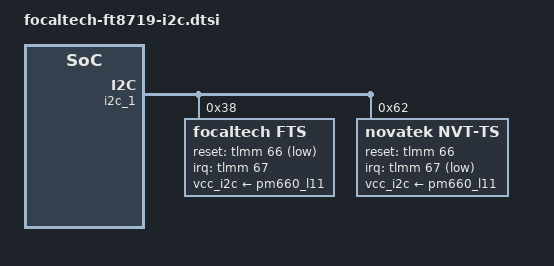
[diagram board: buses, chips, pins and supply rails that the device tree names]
/*
 * This program is free software; you can redistribute it and/or modify
 * it under the terms of the GNU General Public License as published by
 * the Free Software Foundation; either version 2 of the License, or
 * (at your option) any later version.
 *
 * This program is distributed in the hope that it will be useful, but WITHOUT
 * ANY WARRANTY; without even the implied warranty of MERCHANTABILITY or
 * FITNESS FOR A PARTICULAR PURPOSE.  See the GNU General Public License for
 * more details.
 *
 */


&i2c_1{
	status = "ok";
		focaltech@38{
				compatible = "focaltech,fts";
				reg = <0x38>;
				interrupt-parent = <&tlmm>;
				interrupts = <67 0x02>;
				vcc_i2c-supply=<&pm660_l11>;
				focaltech,reset-gpio = <&tlmm 66 0x01>;
				focaltech,irq-gpio = <&tlmm 67 0x02>;
				focaltech,max-touch-number = <10>;
				focaltech,display-coords =  <0 0 1080 2280>;

				pinctrl-names = "pmx_ts_active","pmx_ts_suspend";
				pinctrl-0 = <&ts_active>;
				pinctrl-1 = <&ts_int_suspend &ts_reset_suspend>;

				focaltech,have-key;
				focaltech,key-number = <0>;
				focaltech,keys = <139 102 158>;
				focaltech,key-y-coord = <2500>;
				focaltech,key-x-coords = <200 600 800>;
		};

		/* Novatek device tree node */

	novatek@62 {
		compatible = "novatek,NVT-ts";
		reg = <0x62>;
		status = "ok";

		vcc_i2c-supply=<&pm660_l11>;

		novatek,reset-gpio = <&tlmm 66 0x00>;
		novatek,irq-gpio = <&tlmm 67 0x2001>;

		/* MP */
		novatek,mp-support-dt;

		novatek-mp-criteria-590B@0 {
			#address-cells = <1>;
			#size-cells = <0>;
			compatible = "novatek-mp-criteria-590B";

			/* MP Config */
			IC_X_CFG_SIZE = <18>;
			IC_Y_CFG_SIZE = <36>;
			IC_KEY_CFG_SIZE = <4>;
			X_Channel = <18>;
			Y_Channel = <36>;
			  AIN_X = <0 1 2 3 4 5 6 7 8 9 10 11 12 13 14 15 16 17>;

			  AIN_Y = <0 1 2 3 4 5 6 7 8 9 10 11 12 13 14 15 16 17
							18 19 20 21 22 23 24 25 26 27 28 29 30 31 32 33 34 35>;

			AIN_KEY = <0 1 2 0xFF>;

			/* MP Criteria */
			PS_Config_Lmt_Short_Rawdata_P = <
				14000 14000 14000 14000 14000 14000 14000 14000 14000 14000 14000 14000 14000 14000 14000 14000 14000 14000
				14000 14000 14000 14000 14000 14000 14000 14000 14000 14000 14000 14000 14000 14000 14000 14000 14000 14000
				14000 14000 14000 14000 14000 14000 14000 14000 14000 14000 14000 14000 14000 14000 14000 14000 14000 14000
				14000 14000 14000 14000 14000 14000 14000 14000 14000 14000 14000 14000 14000 14000 14000 14000 14000 14000
				14000 14000 14000 14000 14000 14000 14000 14000 14000 14000 14000 14000 14000 14000 14000 14000 14000 14000
				14000 14000 14000 14000 14000 14000 14000 14000 14000 14000 14000 14000 14000 14000 14000 14000 14000 14000
				14000 14000 14000 14000 14000 14000 14000 14000 14000 14000 14000 14000 14000 14000 14000 14000 14000 14000
				14000 14000 14000 14000 14000 14000 14000 14000 14000 14000 14000 14000 14000 14000 14000 14000 14000 14000
				14000 14000 14000 14000 14000 14000 14000 14000 14000 14000 14000 14000 14000 14000 14000 14000 14000 14000
				14000 14000 14000 14000 14000 14000 14000 14000 14000 14000 14000 14000 14000 14000 14000 14000 14000 14000
				14000 14000 14000 14000 14000 14000 14000 14000 14000 14000 14000 14000 14000 14000 14000 14000 14000 14000
				14000 14000 14000 14000 14000 14000 14000 14000 14000 14000 14000 14000 14000 14000 14000 14000 14000 14000
				14000 14000 14000 14000 14000 14000 14000 14000 14000 14000 14000 14000 14000 14000 14000 14000 14000 14000
				14000 14000 14000 14000 14000 14000 14000 14000 14000 14000 14000 14000 14000 14000 14000 14000 14000 14000
				14000 14000 14000 14000 14000 14000 14000 14000 14000 14000 14000 14000 14000 14000 14000 14000 14000 14000
				14000 14000 14000 14000 14000 14000 14000 14000 14000 14000 14000 14000 14000 14000 14000 14000 14000 14000
				14000 14000 14000 14000 14000 14000 14000 14000 14000 14000 14000 14000 14000 14000 14000 14000 14000 14000
				14000 14000 14000 14000 14000 14000 14000 14000 14000 14000 14000 14000 14000 14000 14000 14000 14000 14000
				14000 14000 14000 14000 14000 14000 14000 14000 14000 14000 14000 14000 14000 14000 14000 14000 14000 14000
				14000 14000 14000 14000 14000 14000 14000 14000 14000 14000 14000 14000 14000 14000 14000 14000 14000 14000
				14000 14000 14000 14000 14000 14000 14000 14000 14000 14000 14000 14000 14000 14000 14000 14000 14000 14000
				14000 14000 14000 14000 14000 14000 14000 14000 14000 14000 14000 14000 14000 14000 14000 14000 14000 14000
				14000 14000 14000 14000 14000 14000 14000 14000 14000 14000 14000 14000 14000 14000 14000 14000 14000 14000
				14000 14000 14000 14000 14000 14000 14000 14000 14000 14000 14000 14000 14000 14000 14000 14000 14000 14000
				14000 14000 14000 14000 14000 14000 14000 14000 14000 14000 14000 14000 14000 14000 14000 14000 14000 14000
				14000 14000 14000 14000 14000 14000 14000 14000 14000 14000 14000 14000 14000 14000 14000 14000 14000 14000
				14000 14000 14000 14000 14000 14000 14000 14000 14000 14000 14000 14000 14000 14000 14000 14000 14000 14000
				14000 14000 14000 14000 14000 14000 14000 14000 14000 14000 14000 14000 14000 14000 14000 14000 14000 14000
				14000 14000 14000 14000 14000 14000 14000 14000 14000 14000 14000 14000 14000 14000 14000 14000 14000 14000
				14000 14000 14000 14000 14000 14000 14000 14000 14000 14000 14000 14000 14000 14000 14000 14000 14000 14000
				14000 14000 14000 14000 14000 14000 14000 14000 14000 14000 14000 14000 14000 14000 14000 14000 14000 14000
				14000 14000 14000 14000 14000 14000 14000 14000 14000 14000 14000 14000 14000 14000 14000 14000 14000 14000
				14000 14000 14000 14000 14000 14000 14000 14000 14000 14000 14000 14000 14000 14000 14000 14000 14000 14000
				14000 14000 14000 14000 14000 14000 14000 14000 14000 14000 14000 14000 14000 14000 14000 14000 14000 14000
				14000 14000 14000 14000 14000 14000 14000 14000 14000 14000 14000 14000 14000 14000 14000 14000 14000 14000
				14000 14000 14000 14000 14000 14000 14000 14000 14000 14000 14000 14000 14000 14000 14000 14000 14000 14000
				20000 20000 20000>;

			PS_Config_Lmt_Short_Rawdata_N = <
				11000 11000 11000 11000 11000 11000 11000 11000 11000 11000 11000 11000 11000 11000 11000 11000 11000 11000
				11000 11000 11000 11000 11000 11000 11000 11000 11000 11000 11000 11000 11000 11000 11000 11000 11000 11000
				11000 11000 11000 11000 11000 11000 11000 11000 11000 11000 11000 11000 11000 11000 11000 11000 11000 11000
				11000 11000 11000 11000 11000 11000 11000 11000 11000 11000 11000 11000 11000 11000 11000 11000 11000 11000
				11000 11000 11000 11000 11000 11000 11000 11000 11000 11000 11000 11000 11000 11000 11000 11000 11000 11000
				11000 11000 11000 11000 11000 11000 11000 11000 11000 11000 11000 11000 11000 11000 11000 11000 11000 11000
				11000 11000 11000 11000 11000 11000 11000 11000 11000 11000 11000 11000 11000 11000 11000 11000 11000 11000
				11000 11000 11000 11000 11000 11000 11000 11000 11000 11000 11000 11000 11000 11000 11000 11000 11000 11000
				11000 11000 11000 11000 11000 11000 11000 11000 11000 11000 11000 11000 11000 11000 11000 11000 11000 11000
				11000 11000 11000 11000 11000 11000 11000 11000 11000 11000 11000 11000 11000 11000 11000 11000 11000 11000
				11000 11000 11000 11000 11000 11000 11000 11000 11000 11000 11000 11000 11000 11000 11000 11000 11000 11000
				11000 11000 11000 11000 11000 11000 11000 11000 11000 11000 11000 11000 11000 11000 11000 11000 11000 11000
				11000 11000 11000 11000 11000 11000 11000 11000 11000 11000 11000 11000 11000 11000 11000 11000 11000 11000
				11000 11000 11000 11000 11000 11000 11000 11000 11000 11000 11000 11000 11000 11000 11000 11000 11000 11000
				11000 11000 11000 11000 11000 11000 11000 11000 11000 11000 11000 11000 11000 11000 11000 11000 11000 11000
				11000 11000 11000 11000 11000 11000 11000 11000 11000 11000 11000 11000 11000 11000 11000 11000 11000 11000
				11000 11000 11000 11000 11000 11000 11000 11000 11000 11000 11000 11000 11000 11000 11000 11000 11000 11000
				11000 11000 11000 11000 11000 11000 11000 11000 11000 11000 11000 11000 11000 11000 11000 11000 11000 11000
				11000 11000 11000 11000 11000 11000 11000 11000 11000 11000 11000 11000 11000 11000 11000 11000 11000 11000
				11000 11000 11000 11000 11000 11000 11000 11000 11000 11000 11000 11000 11000 11000 11000 11000 11000 11000
				11000 11000 11000 11000 11000 11000 11000 11000 11000 11000 11000 11000 11000 11000 11000 11000 11000 11000
				11000 11000 11000 11000 11000 11000 11000 11000 11000 11000 11000 11000 11000 11000 11000 11000 11000 11000
				11000 11000 11000 11000 11000 11000 11000 11000 11000 11000 11000 11000 11000 11000 11000 11000 11000 11000
				11000 11000 11000 11000 11000 11000 11000 11000 11000 11000 11000 11000 11000 11000 11000 11000 11000 11000
				11000 11000 11000 11000 11000 11000 11000 11000 11000 11000 11000 11000 11000 11000 11000 11000 11000 11000
				11000 11000 11000 11000 11000 11000 11000 11000 11000 11000 11000 11000 11000 11000 11000 11000 11000 11000
				11000 11000 11000 11000 11000 11000 11000 11000 11000 11000 11000 11000 11000 11000 11000 11000 11000 11000
				11000 11000 11000 11000 11000 11000 11000 11000 11000 11000 11000 11000 11000 11000 11000 11000 11000 11000
				11000 11000 11000 11000 11000 11000 11000 11000 11000 11000 11000 11000 11000 11000 11000 11000 11000 11000
				11000 11000 11000 11000 11000 11000 11000 11000 11000 11000 11000 11000 11000 11000 11000 11000 11000 11000
				11000 11000 11000 11000 11000 11000 11000 11000 11000 11000 11000 11000 11000 11000 11000 11000 11000 11000
				11000 11000 11000 11000 11000 11000 11000 11000 11000 11000 11000 11000 11000 11000 11000 11000 11000 11000
				11000 11000 11000 11000 11000 11000 11000 11000 11000 11000 11000 11000 11000 11000 11000 11000 11000 11000
				11000 11000 11000 11000 11000 11000 11000 11000 11000 11000 11000 11000 11000 11000 11000 11000 11000 11000
				11000 11000 11000 11000 11000 11000 11000 11000 11000 11000 11000 11000 11000 11000 11000 11000 11000 11000
				11000 11000 11000 11000 11000 11000 11000 11000 11000 11000 11000 11000 11000 11000 11000 11000 11000 11000
				11550 11550 11550>;

			PS_Config_Lmt_Short_Diff_P = <
				6300 6300 6300 6300 6300 6300 6300 6300 6300 6300 6300 6300 6300 6300 6300 6300 6300 6300
				6300 6300 6300 6300 6300 6300 6300 6300 6300 6300 6300 6300 6300 6300 6300 6300 6300 6300
				6300 6300 6300 6300 6300 6300 6300 6300 6300 6300 6300 6300 6300 6300 6300 6300 6300 6300
				6300 6300 6300 6300 6300 6300 6300 6300 6300 6300 6300 6300 6300 6300 6300 6300 6300 6300
				6300 6300 6300 6300 6300 6300 6300 6300 6300 6300 6300 6300 6300 6300 6300 6300 6300 6300
				6300 6300 6300 6300 6300 6300 6300 6300 6300 6300 6300 6300 6300 6300 6300 6300 6300 6300
				6300 6300 6300 6300 6300 6300 6300 6300 6300 6300 6300 6300 6300 6300 6300 6300 6300 6300
				6300 6300 6300 6300 6300 6300 6300 6300 6300 6300 6300 6300 6300 6300 6300 6300 6300 6300
				6300 6300 6300 6300 6300 6300 6300 6300 6300 6300 6300 6300 6300 6300 6300 6300 6300 6300
				6300 6300 6300 6300 6300 6300 6300 6300 6300 6300 6300 6300 6300 6300 6300 6300 6300 6300
				6300 6300 6300 6300 6300 6300 6300 6300 6300 6300 6300 6300 6300 6300 6300 6300 6300 6300
				6300 6300 6300 6300 6300 6300 6300 6300 6300 6300 6300 6300 6300 6300 6300 6300 6300 6300
				6300 6300 6300 6300 6300 6300 6300 6300 6300 6300 6300 6300 6300 6300 6300 6300 6300 6300
				6300 6300 6300 6300 6300 6300 6300 6300 6300 6300 6300 6300 6300 6300 6300 6300 6300 6300
				6300 6300 6300 6300 6300 6300 6300 6300 6300 6300 6300 6300 6300 6300 6300 6300 6300 6300
				6300 6300 6300 6300 6300 6300 6300 6300 6300 6300 6300 6300 6300 6300 6300 6300 6300 6300
				6300 6300 6300 6300 6300 6300 6300 6300 6300 6300 6300 6300 6300 6300 6300 6300 6300 6300
				6300 6300 6300 6300 6300 6300 6300 6300 6300 6300 6300 6300 6300 6300 6300 6300 6300 6300
				6300 6300 6300 6300 6300 6300 6300 6300 6300 6300 6300 6300 6300 6300 6300 6300 6300 6300
				6300 6300 6300 6300 6300 6300 6300 6300 6300 6300 6300 6300 6300 6300 6300 6300 6300 6300
				6300 6300 6300 6300 6300 6300 6300 6300 6300 6300 6300 6300 6300 6300 6300 6300 6300 6300
				6300 6300 6300 6300 6300 6300 6300 6300 6300 6300 6300 6300 6300 6300 6300 6300 6300 6300
				6300 6300 6300 6300 6300 6300 6300 6300 6300 6300 6300 6300 6300 6300 6300 6300 6300 6300
				6300 6300 6300 6300 6300 6300 6300 6300 6300 6300 6300 6300 6300 6300 6300 6300 6300 6300
				6300 6300 6300 6300 6300 6300 6300 6300 6300 6300 6300 6300 6300 6300 6300 6300 6300 6300
				6300 6300 6300 6300 6300 6300 6300 6300 6300 6300 6300 6300 6300 6300 6300 6300 6300 6300
				6300 6300 6300 6300 6300 6300 6300 6300 6300 6300 6300 6300 6300 6300 6300 6300 6300 6300
				6300 6300 6300 6300 6300 6300 6300 6300 6300 6300 6300 6300 6300 6300 6300 6300 6300 6300
				6300 6300 6300 6300 6300 6300 6300 6300 6300 6300 6300 6300 6300 6300 6300 6300 6300 6300
				6300 6300 6300 6300 6300 6300 6300 6300 6300 6300 6300 6300 6300 6300 6300 6300 6300 6300
				6300 6300 6300 6300 6300 6300 6300 6300 6300 6300 6300 6300 6300 6300 6300 6300 6300 6300
				6300 6300 6300 6300 6300 6300 6300 6300 6300 6300 6300 6300 6300 6300 6300 6300 6300 6300
				6300 6300 6300>;

			PS_Config_Lmt_Short_Diff_N = <
				0 0 0 0 0 0 0 0 0 0 0 0 0 0 0 0 0 0
				0 0 0 0 0 0 0 0 0 0 0 0 0 0 0 0 0 0
				0 0 0 0 0 0 0 0 0 0 0 0 0 0 0 0 0 0
				0 0 0 0 0 0 0 0 0 0 0 0 0 0 0 0 0 0
				0 0 0 0 0 0 0 0 0 0 0 0 0 0 0 0 0 0
				0 0 0 0 0 0 0 0 0 0 0 0 0 0 0 0 0 0
				0 0 0 0 0 0 0 0 0 0 0 0 0 0 0 0 0 0
				0 0 0 0 0 0 0 0 0 0 0 0 0 0 0 0 0 0
				0 0 0 0 0 0 0 0 0 0 0 0 0 0 0 0 0 0
				0 0 0 0 0 0 0 0 0 0 0 0 0 0 0 0 0 0
				0 0 0 0 0 0 0 0 0 0 0 0 0 0 0 0 0 0
				0 0 0 0 0 0 0 0 0 0 0 0 0 0 0 0 0 0
				0 0 0 0 0 0 0 0 0 0 0 0 0 0 0 0 0 0
				0 0 0 0 0 0 0 0 0 0 0 0 0 0 0 0 0 0
				0 0 0 0 0 0 0 0 0 0 0 0 0 0 0 0 0 0
				0 0 0 0 0 0 0 0 0 0 0 0 0 0 0 0 0 0
				0 0 0 0 0 0 0 0 0 0 0 0 0 0 0 0 0 0
				0 0 0 0 0 0 0 0 0 0 0 0 0 0 0 0 0 0
				0 0 0 0 0 0 0 0 0 0 0 0 0 0 0 0 0 0
				0 0 0 0 0 0 0 0 0 0 0 0 0 0 0 0 0 0
				0 0 0 0 0 0 0 0 0 0 0 0 0 0 0 0 0 0
				0 0 0 0 0 0 0 0 0 0 0 0 0 0 0 0 0 0
				0 0 0 0 0 0 0 0 0 0 0 0 0 0 0 0 0 0
				0 0 0 0 0 0 0 0 0 0 0 0 0 0 0 0 0 0
				0 0 0 0 0 0 0 0 0 0 0 0 0 0 0 0 0 0
				0 0 0 0 0 0 0 0 0 0 0 0 0 0 0 0 0 0
				0 0 0 0 0 0 0 0 0 0 0 0 0 0 0 0 0 0
				0 0 0 0 0 0 0 0 0 0 0 0 0 0 0 0 0 0
				0 0 0 0 0 0 0 0 0 0 0 0 0 0 0 0 0 0
				0 0 0 0 0 0 0 0 0 0 0 0 0 0 0 0 0 0
				0 0 0 0 0 0 0 0 0 0 0 0 0 0 0 0 0 0
				0 0 0 0 0 0 0 0 0 0 0 0 0 0 0 0 0 0
				0 0 0>;

			PS_Config_Lmt_Short_Base_P = <
				2000 2000 2000 2000 2000 2000 2000 2000 2000 2000 2000 2000 2000 2000 2000 2000 2000 2000
				2000 2000 2000 2000 2000 2000 2000 2000 2000 2000 2000 2000 2000 2000 2000 2000 2000 2000
				2000 2000 2000 2000 2000 2000 2000 2000 2000 2000 2000 2000 2000 2000 2000 2000 2000 2000
				2000 2000 2000 2000 2000 2000 2000 2000 2000 2000 2000 2000 2000 2000 2000 2000 2000 2000
				2000 2000 2000 2000 2000 2000 2000 2000 2000 2000 2000 2000 2000 2000 2000 2000 2000 2000
				2000 2000 2000 2000 2000 2000 2000 2000 2000 2000 2000 2000 2000 2000 2000 2000 2000 2000
				2000 2000 2000 2000 2000 2000 2000 2000 2000 2000 2000 2000 2000 2000 2000 2000 2000 2000
				2000 2000 2000 2000 2000 2000 2000 2000 2000 2000 2000 2000 2000 2000 2000 2000 2000 2000
				2000 2000 2000 2000 2000 2000 2000 2000 2000 2000 2000 2000 2000 2000 2000 2000 2000 2000
				2000 2000 2000 2000 2000 2000 2000 2000 2000 2000 2000 2000 2000 2000 2000 2000 2000 2000
				2000 2000 2000 2000 2000 2000 2000 2000 2000 2000 2000 2000 2000 2000 2000 2000 2000 2000
				2000 2000 2000 2000 2000 2000 2000 2000 2000 2000 2000 2000 2000 2000 2000 2000 2000 2000
				2000 2000 2000 2000 2000 2000 2000 2000 2000 2000 2000 2000 2000 2000 2000 2000 2000 2000
				2000 2000 2000 2000 2000 2000 2000 2000 2000 2000 2000 2000 2000 2000 2000 2000 2000 2000
				2000 2000 2000 2000 2000 2000 2000 2000 2000 2000 2000 2000 2000 2000 2000 2000 2000 2000
				2000 2000 2000 2000 2000 2000 2000 2000 2000 2000 2000 2000 2000 2000 2000 2000 2000 2000
				2000 2000 2000 2000 2000 2000 2000 2000 2000 2000 2000 2000 2000 2000 2000 2000 2000 2000
				2000 2000 2000 2000 2000 2000 2000 2000 2000 2000 2000 2000 2000 2000 2000 2000 2000 2000
				2000 2000 2000 2000 2000 2000 2000 2000 2000 2000 2000 2000 2000 2000 2000 2000 2000 2000
				2000 2000 2000 2000 2000 2000 2000 2000 2000 2000 2000 2000 2000 2000 2000 2000 2000 2000
				2000 2000 2000 2000 2000 2000 2000 2000 2000 2000 2000 2000 2000 2000 2000 2000 2000 2000
				2000 2000 2000 2000 2000 2000 2000 2000 2000 2000 2000 2000 2000 2000 2000 2000 2000 2000
				2000 2000 2000 2000 2000 2000 2000 2000 2000 2000 2000 2000 2000 2000 2000 2000 2000 2000
				2000 2000 2000 2000 2000 2000 2000 2000 2000 2000 2000 2000 2000 2000 2000 2000 2000 2000
				2000 2000 2000 2000 2000 2000 2000 2000 2000 2000 2000 2000 2000 2000 2000 2000 2000 2000
				2000 2000 2000 2000 2000 2000 2000 2000 2000 2000 2000 2000 2000 2000 2000 2000 2000 2000
				2000 2000 2000 2000 2000 2000 2000 2000 2000 2000 2000 2000 2000 2000 2000 2000 2000 2000
				2000 2000 2000 2000 2000 2000 2000 2000 2000 2000 2000 2000 2000 2000 2000 2000 2000 2000
				2000 2000 2000 2000 2000 2000 2000 2000 2000 2000 2000 2000 2000 2000 2000 2000 2000 2000
				2000 2000 2000 2000 2000 2000 2000 2000 2000 2000 2000 2000 2000 2000 2000 2000 2000 2000
				2000 2000 2000 2000 2000 2000 2000 2000 2000 2000 2000 2000 2000 2000 2000 2000 2000 2000
				2000 2000 2000 2000 2000 2000 2000 2000 2000 2000 2000 2000 2000 2000 2000 2000 2000 2000
				2000 2000 2000>;

			PS_Config_Lmt_Short_Base_N = <
				(-2000) (-2000) (-2000) (-2000) (-2000) (-2000) (-2000) (-2000) (-2000) (-2000) (-2000) (-2000) (-2000) (-2000) (-2000) (-2000) (-2000) (-2000)
				(-2000) (-2000) (-2000) (-2000) (-2000) (-2000) (-2000) (-2000) (-2000) (-2000) (-2000) (-2000) (-2000) (-2000) (-2000) (-2000) (-2000) (-2000)
				(-2000) (-2000) (-2000) (-2000) (-2000) (-2000) (-2000) (-2000) (-2000) (-2000) (-2000) (-2000) (-2000) (-2000) (-2000) (-2000) (-2000) (-2000)
				(-2000) (-2000) (-2000) (-2000) (-2000) (-2000) (-2000) (-2000) (-2000) (-2000) (-2000) (-2000) (-2000) (-2000) (-2000) (-2000) (-2000) (-2000)
				(-2000) (-2000) (-2000) (-2000) (-2000) (-2000) (-2000) (-2000) (-2000) (-2000) (-2000) (-2000) (-2000) (-2000) (-2000) (-2000) (-2000) (-2000)
				(-2000) (-2000) (-2000) (-2000) (-2000) (-2000) (-2000) (-2000) (-2000) (-2000) (-2000) (-2000) (-2000) (-2000) (-2000) (-2000) (-2000) (-2000)
				(-2000) (-2000) (-2000) (-2000) (-2000) (-2000) (-2000) (-2000) (-2000) (-2000) (-2000) (-2000) (-2000) (-2000) (-2000) (-2000) (-2000) (-2000)
				(-2000) (-2000) (-2000) (-2000) (-2000) (-2000) (-2000) (-2000) (-2000) (-2000) (-2000) (-2000) (-2000) (-2000) (-2000) (-2000) (-2000) (-2000)
				(-2000) (-2000) (-2000) (-2000) (-2000) (-2000) (-2000) (-2000) (-2000) (-2000) (-2000) (-2000) (-2000) (-2000) (-2000) (-2000) (-2000) (-2000)
				(-2000) (-2000) (-2000) (-2000) (-2000) (-2000) (-2000) (-2000) (-2000) (-2000) (-2000) (-2000) (-2000) (-2000) (-2000) (-2000) (-2000) (-2000)
				(-2000) (-2000) (-2000) (-2000) (-2000) (-2000) (-2000) (-2000) (-2000) (-2000) (-2000) (-2000) (-2000) (-2000) (-2000) (-2000) (-2000) (-2000)
				(-2000) (-2000) (-2000) (-2000) (-2000) (-2000) (-2000) (-2000) (-2000) (-2000) (-2000) (-2000) (-2000) (-2000) (-2000) (-2000) (-2000) (-2000)
				(-2000) (-2000) (-2000) (-2000) (-2000) (-2000) (-2000) (-2000) (-2000) (-2000) (-2000) (-2000) (-2000) (-2000) (-2000) (-2000) (-2000) (-2000)
				(-2000) (-2000) (-2000) (-2000) (-2000) (-2000) (-2000) (-2000) (-2000) (-2000) (-2000) (-2000) (-2000) (-2000) (-2000) (-2000) (-2000) (-2000)
				(-2000) (-2000) (-2000) (-2000) (-2000) (-2000) (-2000) (-2000) (-2000) (-2000) (-2000) (-2000) (-2000) (-2000) (-2000) (-2000) (-2000) (-2000)
				(-2000) (-2000) (-2000) (-2000) (-2000) (-2000) (-2000) (-2000) (-2000) (-2000) (-2000) (-2000) (-2000) (-2000) (-2000) (-2000) (-2000) (-2000)
				(-2000) (-2000) (-2000) (-2000) (-2000) (-2000) (-2000) (-2000) (-2000) (-2000) (-2000) (-2000) (-2000) (-2000) (-2000) (-2000) (-2000) (-2000)
				(-2000) (-2000) (-2000) (-2000) (-2000) (-2000) (-2000) (-2000) (-2000) (-2000) (-2000) (-2000) (-2000) (-2000) (-2000) (-2000) (-2000) (-2000)
				(-2000) (-2000) (-2000) (-2000) (-2000) (-2000) (-2000) (-2000) (-2000) (-2000) (-2000) (-2000) (-2000) (-2000) (-2000) (-2000) (-2000) (-2000)
				(-2000) (-2000) (-2000) (-2000) (-2000) (-2000) (-2000) (-2000) (-2000) (-2000) (-2000) (-2000) (-2000) (-2000) (-2000) (-2000) (-2000) (-2000)
				(-2000) (-2000) (-2000) (-2000) (-2000) (-2000) (-2000) (-2000) (-2000) (-2000) (-2000) (-2000) (-2000) (-2000) (-2000) (-2000) (-2000) (-2000)
				(-2000) (-2000) (-2000) (-2000) (-2000) (-2000) (-2000) (-2000) (-2000) (-2000) (-2000) (-2000) (-2000) (-2000) (-2000) (-2000) (-2000) (-2000)
				(-2000) (-2000) (-2000) (-2000) (-2000) (-2000) (-2000) (-2000) (-2000) (-2000) (-2000) (-2000) (-2000) (-2000) (-2000) (-2000) (-2000) (-2000)
				(-2000) (-2000) (-2000) (-2000) (-2000) (-2000) (-2000) (-2000) (-2000) (-2000) (-2000) (-2000) (-2000) (-2000) (-2000) (-2000) (-2000) (-2000)
				(-2000) (-2000) (-2000) (-2000) (-2000) (-2000) (-2000) (-2000) (-2000) (-2000) (-2000) (-2000) (-2000) (-2000) (-2000) (-2000) (-2000) (-2000)
				(-2000) (-2000) (-2000) (-2000) (-2000) (-2000) (-2000) (-2000) (-2000) (-2000) (-2000) (-2000) (-2000) (-2000) (-2000) (-2000) (-2000) (-2000)
				(-2000) (-2000) (-2000) (-2000) (-2000) (-2000) (-2000) (-2000) (-2000) (-2000) (-2000) (-2000) (-2000) (-2000) (-2000) (-2000) (-2000) (-2000)
				(-2000) (-2000) (-2000) (-2000) (-2000) (-2000) (-2000) (-2000) (-2000) (-2000) (-2000) (-2000) (-2000) (-2000) (-2000) (-2000) (-2000) (-2000)
				(-2000) (-2000) (-2000) (-2000) (-2000) (-2000) (-2000) (-2000) (-2000) (-2000) (-2000) (-2000) (-2000) (-2000) (-2000) (-2000) (-2000) (-2000)
				(-2000) (-2000) (-2000) (-2000) (-2000) (-2000) (-2000) (-2000) (-2000) (-2000) (-2000) (-2000) (-2000) (-2000) (-2000) (-2000) (-2000) (-2000)
				(-2000) (-2000) (-2000) (-2000) (-2000) (-2000) (-2000) (-2000) (-2000) (-2000) (-2000) (-2000) (-2000) (-2000) (-2000) (-2000) (-2000) (-2000)
				(-2000) (-2000) (-2000) (-2000) (-2000) (-2000) (-2000) (-2000) (-2000) (-2000) (-2000) (-2000) (-2000) (-2000) (-2000) (-2000) (-2000) (-2000)
				(-2000) (-2000) (-2000)>;

			PS_Config_Lmt_Open_Rawdata_P = <
				2125 3088 3111 3114 2187 5120 5120 5120 5120 5120 5120 5120 5120 2144 3136 3151 3116 2144
				2868 2880 2868 2868 2258 2293 2274 2269 2261 2269 2275 2285 2295 2257 2876 2886 2892 2896
				2934 2919 2909 2910 2901 2887 2885 2870 2857 2873 2880 2894 2888 2891 2916 2926 2930 2945
				2924 2919 2918 2919 2910 2894 2891 2874 2865 2876 2882 2903 2898 2903 2927 2936 2942 2951
				2934 2912 2906 2906 2895 2879 2877 2859 2850 2890 2894 2905 2903 2908 2931 2940 2946 2956
				2939 2925 2920 2919 2908 2891 2889 2871 2863 2898 2903 2912 2911 2917 2941 2947 2954 2961
				2924 2925 2918 2916 2906 2889 2886 2867 2864 2888 2892 2900 2902 2908 2930 2937 2943 2948
				2935 2938 2925 2922 2919 2903 2899 2880 2879 2903 2906 2901 2896 2918 2939 2943 2951 2954
				2933 2932 2927 2922 2912 2896 2893 2872 2872 2894 2897 2902 2896 2910 2933 2936 2942 2943
				2944 2926 2922 2916 2907 2890 2886 2868 2867 2898 2898 2903 2899 2912 2934 2937 2943 2943
				2936 2938 2935 2928 2909 2895 2898 2883 2881 2904 2899 2905 2904 2910 2930 2941 2946 2944
				2928 2932 2932 2924 2911 2896 2893 2878 2878 2919 2913 2919 2918 2932 2949 2952 2957 2955
				2939 2930 2929 2921 2908 2894 2891 2876 2875 2907 2902 2908 2907 2919 2937 2941 2943 2940
				2932 2926 2924 2916 2902 2890 2886 2876 2873 2904 2899 2904 2903 2917 2933 2937 2936 2934
				2928 2922 2926 2916 2902 2890 2881 2875 2875 2907 2901 2910 2907 2920 2936 2934 2931 2934
				2923 2926 2929 2920 2906 2892 2895 2885 2880 2897 2893 2900 2899 2914 2927 2931 2928 2925
				2922 2915 2918 2908 2894 2880 2882 2883 2867 2890 2884 2891 2892 2905 2918 2922 2918 2917
				2923 2911 2916 2907 2890 2878 2880 2876 2866 2903 2900 2904 2904 2918 2928 2933 2928 2931
				2910 2904 2906 2896 2883 2869 2872 2868 2855 2882 2876 2884 2884 2900 2910 2914 2908 2906
				2904 2902 2903 2894 2879 2867 2871 2867 2861 2880 2874 2885 2884 2900 2908 2913 2905 2910
				2895 2889 2890 2881 2866 2854 2858 2854 2854 2880 2873 2884 2883 2899 2906 2910 2907 2909
				2889 2891 2897 2888 2871 2860 2866 2860 2859 2876 2867 2883 2881 2898 2903 2908 2905 2908
				2880 2880 2881 2871 2855 2845 2851 2847 2844 2866 2857 2871 2869 2886 2891 2893 2889 2890
				2645 2631 2635 2627 2617 2606 2609 2605 2601 2623 2620 2633 2637 2647 2651 2651 2645 2651
				2636 2618 2623 2617 2608 2596 2601 2596 2592 2615 2612 2629 2629 2640 2645 2644 2640 2646
				2631 2630 2631 2624 2618 2607 2614 2607 2603 2617 2616 2629 2627 2641 2646 2646 2642 2650
				2616 2617 2619 2612 2605 2593 2599 2595 2590 2605 2603 2619 2618 2628 2633 2633 2630 2638
				2626 2618 2621 2613 2605 2598 2602 2597 2592 2601 2599 2613 2613 2623 2628 2627 2626 2634
				2611 2609 2611 2603 2593 2585 2595 2587 2582 2585 2584 2597 2596 2604 2608 2611 2611 2621
				2613 2598 2600 2592 2584 2576 2583 2576 2571 2589 2588 2600 2599 2610 2613 2614 2614 2625
				2603 2580 2580 2573 2565 2558 2565 2558 2554 2575 2577 2586 2586 2596 2600 2602 2602 2612
				2592 2581 2581 2574 2565 2559 2567 2559 2555 2571 2571 2581 2581 2592 2594 2596 2599 2608
				2571 2567 2567 2560 2553 2545 2553 2543 2540 2549 2551 2560 2561 2572 2574 2574 2576 2589
				2571 2552 2553 2546 2540 2531 2542 2532 2527 2754 2757 2764 2765 2784 2785 2786 2787 2801
				2518 2503 2502 2497 2490 2480 2494 2480 2475 2497 2502 2519 2506 2514 2519 2524 2526 2542
				2196 2972 2984 2983 2970 2958 2972 2956 2950 2760 2766 2784 2775 2786 2787 2787 2779 2002
				13000 13000 13000>;

			PS_Config_Lmt_Open_Rawdata_N = <
				1221 1775 1788 1790 1257   50   50   50   50   50   50   50   50 1232 1802 1811 1791 1233
				1649 1655 1649 1649 1298 1318 1307 1304 1300 1304 1308 1313 1319 1298 1653 1659 1663 1665
				1687 1678 1672 1672 1668 1659 1659 1649 1642 1651 1655 1663 1660 1662 1676 1682 1684 1693
				1681 1678 1678 1678 1673 1664 1662 1652 1647 1653 1657 1669 1666 1668 1682 1688 1691 1696
				1686 1674 1670 1670 1664 1655 1654 1643 1638 1661 1664 1670 1669 1672 1685 1690 1693 1699
				1689 1681 1679 1678 1671 1662 1661 1650 1646 1666 1668 1674 1673 1677 1690 1694 1698 1702
				1681 1681 1677 1676 1671 1661 1659 1648 1646 1660 1663 1667 1668 1672 1684 1688 1692 1694
				1687 1689 1681 1679 1678 1669 1666 1655 1655 1669 1670 1667 1665 1677 1690 1692 1696 1698
				1686 1685 1682 1680 1674 1665 1663 1651 1651 1664 1665 1668 1665 1673 1686 1688 1691 1691
				1692 1682 1679 1676 1671 1661 1659 1649 1648 1666 1666 1669 1666 1674 1686 1688 1691 1691
				1688 1688 1687 1683 1672 1664 1666 1657 1656 1669 1666 1670 1669 1673 1684 1691 1693 1692
				1683 1685 1685 1681 1673 1665 1663 1655 1654 1678 1674 1678 1677 1685 1695 1697 1700 1699
				1689 1684 1683 1679 1672 1664 1662 1653 1653 1671 1668 1672 1671 1678 1688 1691 1692 1690
				1686 1682 1681 1676 1668 1661 1659 1653 1651 1669 1666 1669 1669 1677 1686 1688 1688 1687
				1683 1680 1682 1676 1668 1661 1656 1652 1652 1671 1667 1673 1671 1679 1687 1686 1685 1687
				1680 1682 1684 1679 1670 1662 1664 1658 1656 1665 1663 1667 1666 1675 1682 1685 1683 1681
				1679 1675 1677 1672 1663 1656 1657 1657 1648 1661 1658 1662 1662 1670 1677 1680 1677 1677
				1680 1674 1676 1671 1661 1654 1656 1653 1647 1668 1667 1669 1669 1677 1683 1686 1683 1685
				1673 1669 1670 1665 1657 1649 1651 1649 1641 1656 1653 1658 1658 1667 1673 1675 1671 1670
				1669 1668 1669 1664 1655 1648 1650 1648 1644 1656 1652 1658 1658 1667 1671 1674 1670 1673
				1664 1661 1661 1656 1647 1640 1643 1640 1640 1656 1652 1658 1657 1667 1670 1673 1671 1672
				1660 1662 1665 1660 1650 1644 1648 1644 1643 1653 1648 1657 1656 1666 1669 1672 1670 1671
				1656 1656 1656 1650 1641 1635 1639 1636 1635 1647 1642 1650 1649 1659 1662 1663 1661 1661
				1520 1512 1515 1510 1504 1498 1499 1497 1495 1508 1506 1514 1516 1521 1524 1524 1520 1524
				1515 1505 1508 1504 1499 1492 1495 1492 1490 1503 1501 1511 1511 1518 1520 1520 1517 1521
				1512 1511 1512 1508 1505 1499 1502 1499 1496 1505 1504 1511 1510 1518 1521 1521 1518 1523
				1503 1504 1505 1501 1497 1491 1494 1492 1489 1497 1496 1505 1505 1510 1513 1513 1512 1516
				1509 1505 1506 1502 1497 1493 1496 1493 1490 1495 1494 1502 1502 1508 1510 1510 1510 1514
				1501 1500 1501 1496 1490 1486 1491 1487 1484 1486 1485 1493 1492 1497 1499 1501 1501 1506
				1502 1494 1495 1490 1485 1481 1485 1481 1478 1488 1488 1494 1494 1500 1502 1503 1503 1509
				1496 1483 1483 1479 1475 1470 1474 1470 1468 1480 1481 1487 1487 1492 1494 1495 1496 1501
				1490 1484 1483 1479 1475 1471 1476 1471 1468 1478 1478 1483 1483 1490 1491 1492 1494 1499
				1478 1476 1475 1471 1467 1463 1467 1462 1460 1465 1466 1471 1472 1478 1479 1479 1481 1488
				1478 1467 1467 1464 1460 1455 1461 1455 1452 1583 1585 1589 1590 1600 1601 1602 1602 1610
				1448 1439 1438 1435 1431 1426 1434 1425 1423 1435 1438 1448 1441 1445 1448 1451 1452 1461
				1262 1708 1715 1714 1707 1700 1708 1699 1696 1586 1590 1600 1595 1601 1602 1602 1597 1151
				6500 6500 6500>;

			PS_Config_Lmt_FW_Rawdata_P = <
				1750 1750 1750 1750 1750 1750 1750 1750 1750 1750 1750 1750 1750 1750 1750 1750 1750 1750
				1750 1750 1750 1750 1750 1750 1750 1750 1750 1750 1750 1750 1750 1750 1750 1750 1750 1750
				1750 1750 1750 1750 1750 1750 1750 1750 1750 1750 1750 1750 1750 1750 1750 1750 1750 1750
				1750 1750 1750 1750 1750 1750 1750 1750 1750 1750 1750 1750 1750 1750 1750 1750 1750 1750
				1750 1750 1750 1750 1750 1750 1750 1750 1750 1750 1750 1750 1750 1750 1750 1750 1750 1750
				1750 1750 1750 1750 1750 1750 1750 1750 1750 1750 1750 1750 1750 1750 1750 1750 1750 1750
				1750 1750 1750 1750 1750 1750 1750 1750 1750 1750 1750 1750 1750 1750 1750 1750 1750 1750
				1750 1750 1750 1750 1750 1750 1750 1750 1750 1750 1750 1750 1750 1750 1750 1750 1750 1750
				1750 1750 1750 1750 1750 1750 1750 1750 1750 1750 1750 1750 1750 1750 1750 1750 1750 1750
				1750 1750 1750 1750 1750 1750 1750 1750 1750 1750 1750 1750 1750 1750 1750 1750 1750 1750
				1750 1750 1750 1750 1750 1750 1750 1750 1750 1750 1750 1750 1750 1750 1750 1750 1750 1750
				1750 1750 1750 1750 1750 1750 1750 1750 1750 1750 1750 1750 1750 1750 1750 1750 1750 1750
				1750 1750 1750 1750 1750 1750 1750 1750 1750 1750 1750 1750 1750 1750 1750 1750 1750 1750
				1750 1750 1750 1750 1750 1750 1750 1750 1750 1750 1750 1750 1750 1750 1750 1750 1750 1750
				1750 1750 1750 1750 1750 1750 1750 1750 1750 1750 1750 1750 1750 1750 1750 1750 1750 1750
				1750 1750 1750 1750 1750 1750 1750 1750 1750 1750 1750 1750 1750 1750 1750 1750 1750 1750
				1750 1750 1750 1750 1750 1750 1750 1750 1750 1750 1750 1750 1750 1750 1750 1750 1750 1750
				1750 1750 1750 1750 1750 1750 1750 1750 1750 1750 1750 1750 1750 1750 1750 1750 1750 1750
				1750 1750 1750 1750 1750 1750 1750 1750 1750 1750 1750 1750 1750 1750 1750 1750 1750 1750
				1750 1750 1750 1750 1750 1750 1750 1750 1750 1750 1750 1750 1750 1750 1750 1750 1750 1750
				1750 1750 1750 1750 1750 1750 1750 1750 1750 1750 1750 1750 1750 1750 1750 1750 1750 1750
				1750 1750 1750 1750 1750 1750 1750 1750 1750 1750 1750 1750 1750 1750 1750 1750 1750 1750
				1750 1750 1750 1750 1750 1750 1750 1750 1750 1750 1750 1750 1750 1750 1750 1750 1750 1750
				1750 1750 1750 1750 1750 1750 1750 1750 1750 1750 1750 1750 1750 1750 1750 1750 1750 1750
				1750 1750 1750 1750 1750 1750 1750 1750 1750 1750 1750 1750 1750 1750 1750 1750 1750 1750
				1750 1750 1750 1750 1750 1750 1750 1750 1750 1750 1750 1750 1750 1750 1750 1750 1750 1750
				1750 1750 1750 1750 1750 1750 1750 1750 1750 1750 1750 1750 1750 1750 1750 1750 1750 1750
				1750 1750 1750 1750 1750 1750 1750 1750 1750 1750 1750 1750 1750 1750 1750 1750 1750 1750
				1750 1750 1750 1750 1750 1750 1750 1750 1750 1750 1750 1750 1750 1750 1750 1750 1750 1750
				1750 1750 1750 1750 1750 1750 1750 1750 1750 1750 1750 1750 1750 1750 1750 1750 1750 1750
				1750 1750 1750 1750 1750 1750 1750 1750 1750 1750 1750 1750 1750 1750 1750 1750 1750 1750
				1750 1750 1750 1750 1750 1750 1750 1750 1750 1750 1750 1750 1750 1750 1750 1750 1750 1750
				1750 1750 1750 1750 1750 1750 1750 1750 1750 1750 1750 1750 1750 1750 1750 1750 1750 1750
				1750 1750 1750 1750 1750 1750 1750 1750 1750 1750 1750 1750 1750 1750 1750 1750 1750 1750
				1750 1750 1750 1750 1750 1750 1750 1750 1750 1750 1750 1750 1750 1750 1750 1750 1750 1750
				1750 1750 1750 1750 1750 1750 1750 1750 1750 1750 1750 1750 1750 1750 1750 1750 1750 1750
				2000 2000 2000>;

			PS_Config_Lmt_FW_Rawdata_N = <
				650 650 650 650 650 650 650 650 650 650 650 650 650 650 650 650 650 650
				650 650 650 650 650 650 650 650 650 650 650 650 650 650 650 650 650 650
				650 650 650 650 650 650 650 650 650 650 650 650 650 650 650 650 650 650
				650 650 650 650 650 650 650 650 650 650 650 650 650 650 650 650 650 650
				650 650 650 650 650 650 650 650 650 650 650 650 650 650 650 650 650 650
				650 650 650 650 650 650 650 650 650 650 650 650 650 650 650 650 650 650
				650 650 650 650 650 650 650 650 650 650 650 650 650 650 650 650 650 650
				650 650 650 650 650 650 650 650 650 650 650 650 650 650 650 650 650 650
				650 650 650 650 650 650 650 650 650 650 650 650 650 650 650 650 650 650
				650 650 650 650 650 650 650 650 650 650 650 650 650 650 650 650 650 650
				650 650 650 650 650 650 650 650 650 650 650 650 650 650 650 650 650 650
				650 650 650 650 650 650 650 650 650 650 650 650 650 650 650 650 650 650
				650 650 650 650 650 650 650 650 650 650 650 650 650 650 650 650 650 650
				650 650 650 650 650 650 650 650 650 650 650 650 650 650 650 650 650 650
				650 650 650 650 650 650 650 650 650 650 650 650 650 650 650 650 650 650
				650 650 650 650 650 650 650 650 650 650 650 650 650 650 650 650 650 650
				650 650 650 650 650 650 650 650 650 650 650 650 650 650 650 650 650 650
				650 650 650 650 650 650 650 650 650 650 650 650 650 650 650 650 650 650
				650 650 650 650 650 650 650 650 650 650 650 650 650 650 650 650 650 650
				650 650 650 650 650 650 650 650 650 650 650 650 650 650 650 650 650 650
				650 650 650 650 650 650 650 650 650 650 650 650 650 650 650 650 650 650
				650 650 650 650 650 650 650 650 650 650 650 650 650 650 650 650 650 650
				650 650 650 650 650 650 650 650 650 650 650 650 650 650 650 650 650 650
				650 650 650 650 650 650 650 650 650 650 650 650 650 650 650 650 650 650
				650 650 650 650 650 650 650 650 650 650 650 650 650 650 650 650 650 650
				650 650 650 650 650 650 650 650 650 650 650 650 650 650 650 650 650 650
				650 650 650 650 650 650 650 650 650 650 650 650 650 650 650 650 650 650
				650 650 650 650 650 650 650 650 650 650 650 650 650 650 650 650 650 650
				650 650 650 650 650 650 650 650 650 650 650 650 650 650 650 650 650 650
				650 650 650 650 650 650 650 650 650 650 650 650 650 650 650 650 650 650
				650 650 650 650 650 650 650 650 650 650 650 650 650 650 650 650 650 650
				650 650 650 650 650 650 650 650 650 650 650 650 650 650 650 650 650 650
				650 650 650 650 650 650 650 650 650 650 650 650 650 650 650 650 650 650
				650 650 650 650 650 650 650 650 650 650 650 650 650 650 650 650 650 650
				650 650 650 650 650 650 650 650 650 650 650 650 650 650 650 650 650 650
				650 650 650 650 650 650 650 650 650 650 650 650 650 650 650 650 650 650
				400 400 400>;

			PS_Config_Lmt_FW_CC_P = <
				118 116 114 113 111 512 512 512 512 512 512 512 512 112 115 116 116 114
				118 116 114 113 111 112 111 111 111 111 115 114 112 111 113 113 114 118
				122 115 113 112 111 110 110 110 109 111 114 114 112 112 113 114 114 118
				124 116 114 113 113 112 111 111 111 112 115 115 114 113 114 115 116 120
				122 115 113 112 111 111 110 110 109 110 113 113 111 111 112 112 113 117
				123 116 115 114 114 113 112 112 111 112 115 114 113 113 114 114 115 119
				121 114 112 112 111 110 110 109 109 112 115 114 113 113 113 114 115 118
				123 116 114 114 113 112 112 111 111 116 117 115 115 114 115 115 116 120
				120 115 113 113 112 111 112 111 110 116 114 113 112 112 112 113 113 118
				122 116 115 115 114 113 113 113 112 118 113 113 112 112 113 113 114 118
				121 114 113 113 112 111 111 111 110 118 113 113 113 112 113 114 114 118
				123 114 113 113 112 111 111 111 111 121 114 114 114 114 114 115 115 120
				120 114 113 113 113 112 112 112 111 119 113 113 113 113 113 114 114 119
				120 116 115 115 114 114 114 115 113 120 114 114 113 113 114 114 115 120
				120 113 112 112 112 111 111 113 110 120 114 114 113 114 115 115 115 120
				122 114 114 113 113 112 113 114 112 120 115 115 114 115 115 115 116 121
				119 114 114 113 113 112 113 114 111 118 113 112 112 112 113 113 114 118
				120 116 115 115 114 114 114 115 113 120 115 114 114 114 114 115 115 121
				120 114 113 112 112 111 112 112 110 119 115 113 113 113 114 114 115 120
				121 115 114 114 113 113 113 113 113 120 115 114 114 114 115 115 116 122
				118 114 114 113 113 112 113 112 112 117 114 112 112 112 113 113 114 120
				120 115 115 115 114 114 115 114 113 118 114 113 112 113 114 114 115 121
				119 113 112 112 111 112 112 112 110 117 113 113 112 113 114 114 115 121
				120 114 113 113 112 112 113 113 111 117 114 115 114 115 115 116 117 123
				117 114 113 113 112 112 113 113 111 114 112 113 112 113 114 114 115 122
				119 116 116 115 115 115 116 117 114 114 113 114 113 114 115 115 116 123
				118 114 113 113 112 113 114 115 112 114 113 113 114 114 115 115 116 123
				121 115 115 114 113 114 115 116 113 115 114 114 115 115 116 117 118 125
				118 115 115 114 114 114 115 116 112 113 112 112 113 113 114 115 116 123
				120 117 116 116 115 116 116 117 114 114 113 113 114 115 116 116 118 125
				119 115 114 113 113 113 113 114 112 113 113 113 114 114 115 116 117 124
				121 116 115 115 114 114 116 116 113 115 115 115 115 116 117 118 120 127
				118 116 115 115 114 114 116 116 113 112 112 112 113 114 114 115 117 124
				120 117 116 116 115 115 118 117 114 112 113 112 113 114 115 116 118 128
				120 114 114 113 113 112 116 115 111 111 115 116 113 113 114 114 115 118
				114 115 113 114 113 113 117 116 113 111 116 117 113 112 113 113 114 113
				119 120 120>;

			PS_Config_Lmt_FW_CC_N = <
				72 71 70 70 68 10 10 10 10 10 10 10 10 68 71 71 71 70
				73 71 70 69 68 68 68 68 68 68 70 70 69 68 69 70 70 73
				75 70 69 69 68 68 67 67 67 68 70 70 69 69 69 70 70 72
				76 71 70 69 69 69 68 68 68 69 71 70 70 70 70 70 71 73
				75 70 69 69 68 68 67 67 67 67 69 69 68 68 69 69 69 72
				75 71 70 70 70 69 69 69 68 69 70 70 69 69 70 70 70 73
				74 70 69 69 68 67 67 67 67 69 70 70 69 69 69 70 70 72
				76 71 70 70 69 69 69 68 68 71 72 71 70 70 70 71 71 74
				74 70 70 69 69 68 68 68 68 71 70 69 69 69 69 69 70 72
				75 71 70 70 70 69 70 69 69 72 69 69 69 69 69 69 70 72
				74 70 69 69 69 68 68 68 68 73 69 69 69 69 69 70 70 72
				75 70 69 69 69 68 68 68 68 74 70 70 70 70 70 70 71 73
				74 70 69 69 69 68 69 69 68 73 69 69 69 69 69 70 70 73
				74 71 71 71 70 70 70 70 69 74 70 70 70 70 70 70 70 73
				74 69 69 69 68 68 68 69 68 74 70 70 69 70 70 70 71 74
				75 70 70 70 69 69 69 70 68 74 71 70 70 70 70 71 71 74
				73 70 70 69 69 69 69 70 68 72 69 69 68 69 69 69 70 73
				74 71 71 70 70 70 70 70 69 73 71 70 70 70 70 70 71 74
				74 70 69 69 69 68 68 69 68 73 70 69 69 69 70 70 70 74
				74 70 70 70 69 69 69 70 69 73 70 70 70 70 70 71 71 75
				73 70 70 70 69 69 69 69 69 72 70 69 68 69 69 69 70 73
				73 71 71 70 70 70 70 70 69 72 70 69 69 69 70 70 70 74
				73 69 69 69 68 68 69 69 68 71 69 69 69 69 70 70 70 74
				73 70 70 69 69 69 69 69 68 72 70 70 70 71 71 71 72 76
				72 70 69 69 69 69 69 70 68 70 69 69 69 69 70 70 71 75
				73 71 71 71 70 70 71 72 70 70 69 70 70 70 70 70 71 75
				72 70 70 69 69 69 70 70 68 70 69 70 70 70 70 71 71 75
				74 71 70 70 70 70 70 71 69 70 70 70 70 71 71 72 72 77
				73 71 70 70 70 70 70 71 69 69 69 69 69 70 70 70 71 75
				73 71 71 71 71 71 71 72 70 70 69 69 70 70 71 71 72 76
				73 70 70 70 69 69 69 70 68 70 69 69 70 70 70 71 72 76
				74 71 71 70 70 70 71 71 69 71 70 70 70 71 72 72 73 78
				73 71 71 70 70 70 71 71 69 69 69 69 69 70 70 71 72 76
				74 71 71 71 70 70 72 72 70 69 69 68 69 70 70 71 73 78
				73 70 70 70 69 69 71 70 68 68 71 71 69 69 70 70 70 73
				70 70 70 70 69 70 72 71 69 68 71 71 69 69 69 69 70 69
				53 54 54>;

			PS_Config_Lmt_FW_CC_I_P = <
				25 25 25 25 25 25 25 25 25 25 25 25 25 25 25 25 25 25
				25 25 25 25 25 25 25 25 25 25 25 25 25 25 25 25 25 25
				25 25 25 25 25 25 25 25 25 25 25 25 25 25 25 25 25 25
				25 25 25 25 25 25 25 25 25 25 25 25 25 25 25 25 25 25
				25 25 25 25 25 25 25 25 25 25 25 25 25 25 25 25 25 25
				25 25 25 25 25 25 25 25 25 25 25 25 25 25 25 25 25 25
				25 25 25 25 25 25 25 25 25 25 25 25 25 25 25 25 25 25
				25 25 25 25 25 25 25 25 25 25 25 25 25 25 25 25 25 25
				25 25 25 25 25 25 25 25 25 25 25 25 25 25 25 25 25 25
				25 25 25 25 25 25 25 25 25 25 25 25 25 25 25 25 25 25
				25 25 25 25 25 25 25 25 25 25 25 25 25 25 25 25 25 25
				25 25 25 25 25 25 25 25 25 25 25 25 25 25 25 25 25 25
				25 25 25 25 25 25 25 25 25 25 25 25 25 25 25 25 25 25
				25 25 25 25 25 25 25 25 25 25 25 25 25 25 25 25 25 25
				25 25 25 25 25 25 25 25 25 25 25 25 25 25 25 25 25 25
				25 25 25 25 25 25 25 25 25 25 25 25 25 25 25 25 25 25
				25 25 25 25 25 25 25 25 25 25 25 25 25 25 25 25 25 25
				25 25 25 25 25 25 25 25 25 25 25 25 25 25 25 25 25 25
				25 25 25 25 25 25 25 25 25 25 25 25 25 25 25 25 25 25
				25 25 25 25 25 25 25 25 25 25 25 25 25 25 25 25 25 25
				25 25 25 25 25 25 25 25 25 25 25 25 25 25 25 25 25 25
				25 25 25 25 25 25 25 25 25 25 25 25 25 25 25 25 25 25
				25 25 25 25 25 25 25 25 25 25 25 25 25 25 25 25 25 25
				25 25 25 25 25 25 25 25 25 25 25 25 25 25 25 25 25 25
				25 25 25 25 25 25 25 25 25 25 25 25 25 25 25 25 25 25
				25 25 25 25 25 25 25 25 25 25 25 25 25 25 25 25 25 25
				25 25 25 25 25 25 25 25 25 25 25 25 25 25 25 25 25 25
				25 25 25 25 25 25 25 25 25 25 25 25 25 25 25 25 25 25
				25 25 25 25 25 25 25 25 25 25 25 25 25 25 25 25 25 25
				25 25 25 25 25 25 25 25 25 25 25 25 25 25 25 25 25 25
				25 25 25 25 25 25 25 25 25 25 25 25 25 25 25 25 25 25
				25 25 25 25 25 25 25 25 25 25 25 25 25 25 25 25 25 25
				25 25 25 25 25 25 25 25 25 25 25 25 25 25 25 25 25 25
				25 25 25 25 25 25 25 25 25 25 25 25 25 25 25 25 25 25
				25 25 25 25 25 25 25 25 25 25 25 25 25 25 25 25 25 25
				25 25 25 25 25 25 25 25 25 25 25 25 25 25 25 25 25 25
				25 25 25>;

			PS_Config_Lmt_FW_CC_I_N = <
				0 0 0 0 0 0 0 0 0 0 0 0 0 0 0 0 0 0
				0 0 0 0 0 0 0 0 0 0 0 0 0 0 0 0 0 0
				0 0 0 0 0 0 0 0 0 0 0 0 0 0 0 0 0 0
				0 0 0 0 0 0 0 0 0 0 0 0 0 0 0 0 0 0
				0 0 0 0 0 0 0 0 0 0 0 0 0 0 0 0 0 0
				0 0 0 0 0 0 0 0 0 0 0 0 0 0 0 0 0 0
				0 0 0 0 0 0 0 0 0 0 0 0 0 0 0 0 0 0
				0 0 0 0 0 0 0 0 0 0 0 0 0 0 0 0 0 0
				0 0 0 0 0 0 0 0 0 0 0 0 0 0 0 0 0 0
				0 0 0 0 0 0 0 0 0 0 0 0 0 0 0 0 0 0
				0 0 0 0 0 0 0 0 0 0 0 0 0 0 0 0 0 0
				0 0 0 0 0 0 0 0 0 0 0 0 0 0 0 0 0 0
				0 0 0 0 0 0 0 0 0 0 0 0 0 0 0 0 0 0
				0 0 0 0 0 0 0 0 0 0 0 0 0 0 0 0 0 0
				0 0 0 0 0 0 0 0 0 0 0 0 0 0 0 0 0 0
				0 0 0 0 0 0 0 0 0 0 0 0 0 0 0 0 0 0
				0 0 0 0 0 0 0 0 0 0 0 0 0 0 0 0 0 0
				0 0 0 0 0 0 0 0 0 0 0 0 0 0 0 0 0 0
				0 0 0 0 0 0 0 0 0 0 0 0 0 0 0 0 0 0
				0 0 0 0 0 0 0 0 0 0 0 0 0 0 0 0 0 0
				0 0 0 0 0 0 0 0 0 0 0 0 0 0 0 0 0 0
				0 0 0 0 0 0 0 0 0 0 0 0 0 0 0 0 0 0
				0 0 0 0 0 0 0 0 0 0 0 0 0 0 0 0 0 0
				0 0 0 0 0 0 0 0 0 0 0 0 0 0 0 0 0 0
				0 0 0 0 0 0 0 0 0 0 0 0 0 0 0 0 0 0
				0 0 0 0 0 0 0 0 0 0 0 0 0 0 0 0 0 0
				0 0 0 0 0 0 0 0 0 0 0 0 0 0 0 0 0 0
				0 0 0 0 0 0 0 0 0 0 0 0 0 0 0 0 0 0
				0 0 0 0 0 0 0 0 0 0 0 0 0 0 0 0 0 0
				0 0 0 0 0 0 0 0 0 0 0 0 0 0 0 0 0 0
				0 0 0 0 0 0 0 0 0 0 0 0 0 0 0 0 0 0
				0 0 0 0 0 0 0 0 0 0 0 0 0 0 0 0 0 0
				0 0 0 0 0 0 0 0 0 0 0 0 0 0 0 0 0 0
				0 0 0 0 0 0 0 0 0 0 0 0 0 0 0 0 0 0
				0 0 0 0 0 0 0 0 0 0 0 0 0 0 0 0 0 0
				0 0 0 0 0 0 0 0 0 0 0 0 0 0 0 0 0 0
				0 0 0>;

			PS_Config_Lmt_FW_CC_Q_P = <
				25 25 25 25 25 25 25 25 25 25 25 25 25 25 25 25 25 25
				25 25 25 25 25 25 25 25 25 25 25 25 25 25 25 25 25 25
				25 25 25 25 25 25 25 25 25 25 25 25 25 25 25 25 25 25
				25 25 25 25 25 25 25 25 25 25 25 25 25 25 25 25 25 25
				25 25 25 25 25 25 25 25 25 25 25 25 25 25 25 25 25 25
				25 25 25 25 25 25 25 25 25 25 25 25 25 25 25 25 25 25
				25 25 25 25 25 25 25 25 25 25 25 25 25 25 25 25 25 25
				25 25 25 25 25 25 25 25 25 25 25 25 25 25 25 25 25 25
				25 25 25 25 25 25 25 25 25 25 25 25 25 25 25 25 25 25
				25 25 25 25 25 25 25 25 25 25 25 25 25 25 25 25 25 25
				25 25 25 25 25 25 25 25 25 25 25 25 25 25 25 25 25 25
				25 25 25 25 25 25 25 25 25 25 25 25 25 25 25 25 25 25
				25 25 25 25 25 25 25 25 25 25 25 25 25 25 25 25 25 25
				25 25 25 25 25 25 25 25 25 25 25 25 25 25 25 25 25 25
				25 25 25 25 25 25 25 25 25 25 25 25 25 25 25 25 25 25
				25 25 25 25 25 25 25 25 25 25 25 25 25 25 25 25 25 25
				25 25 25 25 25 25 25 25 25 25 25 25 25 25 25 25 25 25
				25 25 25 25 25 25 25 25 25 25 25 25 25 25 25 25 25 25
				25 25 25 25 25 25 25 25 25 25 25 25 25 25 25 25 25 25
				25 25 25 25 25 25 25 25 25 25 25 25 25 25 25 25 25 25
				25 25 25 25 25 25 25 25 25 25 25 25 25 25 25 25 25 25
				25 25 25 25 25 25 25 25 25 25 25 25 25 25 25 25 25 25
				25 25 25 25 25 25 25 25 25 25 25 25 25 25 25 25 25 25
				25 25 25 25 25 25 25 25 25 25 25 25 25 25 25 25 25 25
				25 25 25 25 25 25 25 25 25 25 25 25 25 25 25 25 25 25
				25 25 25 25 25 25 25 25 25 25 25 25 25 25 25 25 25 25
				25 25 25 25 25 25 25 25 25 25 25 25 25 25 25 25 25 25
				25 25 25 25 25 25 25 25 25 25 25 25 25 25 25 25 25 25
				25 25 25 25 25 25 25 25 25 25 25 25 25 25 25 25 25 25
				25 25 25 25 25 25 25 25 25 25 25 25 25 25 25 25 25 25
				25 25 25 25 25 25 25 25 25 25 25 25 25 25 25 25 25 25
				25 25 25 25 25 25 25 25 25 25 25 25 25 25 25 25 25 25
				25 25 25 25 25 25 25 25 25 25 25 25 25 25 25 25 25 25
				25 25 25 25 25 25 25 25 25 25 25 25 25 25 25 25 25 25
				25 25 25 25 25 25 25 25 25 25 25 25 25 25 25 25 25 25
				25 25 25 25 25 25 25 25 25 25 25 25 25 25 25 25 25 25
				25 25 25>;

			PS_Config_Lmt_FW_CC_Q_N = <
				0 0 0 0 0 0 0 0 0 0 0 0 0 0 0 0 0 0
				0 0 0 0 0 0 0 0 0 0 0 0 0 0 0 0 0 0
				0 0 0 0 0 0 0 0 0 0 0 0 0 0 0 0 0 0
				0 0 0 0 0 0 0 0 0 0 0 0 0 0 0 0 0 0
				0 0 0 0 0 0 0 0 0 0 0 0 0 0 0 0 0 0
				0 0 0 0 0 0 0 0 0 0 0 0 0 0 0 0 0 0
				0 0 0 0 0 0 0 0 0 0 0 0 0 0 0 0 0 0
				0 0 0 0 0 0 0 0 0 0 0 0 0 0 0 0 0 0
				0 0 0 0 0 0 0 0 0 0 0 0 0 0 0 0 0 0
				0 0 0 0 0 0 0 0 0 0 0 0 0 0 0 0 0 0
				0 0 0 0 0 0 0 0 0 0 0 0 0 0 0 0 0 0
				0 0 0 0 0 0 0 0 0 0 0 0 0 0 0 0 0 0
				0 0 0 0 0 0 0 0 0 0 0 0 0 0 0 0 0 0
				0 0 0 0 0 0 0 0 0 0 0 0 0 0 0 0 0 0
				0 0 0 0 0 0 0 0 0 0 0 0 0 0 0 0 0 0
				0 0 0 0 0 0 0 0 0 0 0 0 0 0 0 0 0 0
				0 0 0 0 0 0 0 0 0 0 0 0 0 0 0 0 0 0
				0 0 0 0 0 0 0 0 0 0 0 0 0 0 0 0 0 0
				0 0 0 0 0 0 0 0 0 0 0 0 0 0 0 0 0 0
				0 0 0 0 0 0 0 0 0 0 0 0 0 0 0 0 0 0
				0 0 0 0 0 0 0 0 0 0 0 0 0 0 0 0 0 0
				0 0 0 0 0 0 0 0 0 0 0 0 0 0 0 0 0 0
				0 0 0 0 0 0 0 0 0 0 0 0 0 0 0 0 0 0
				0 0 0 0 0 0 0 0 0 0 0 0 0 0 0 0 0 0
				0 0 0 0 0 0 0 0 0 0 0 0 0 0 0 0 0 0
				0 0 0 0 0 0 0 0 0 0 0 0 0 0 0 0 0 0
				0 0 0 0 0 0 0 0 0 0 0 0 0 0 0 0 0 0
				0 0 0 0 0 0 0 0 0 0 0 0 0 0 0 0 0 0
				0 0 0 0 0 0 0 0 0 0 0 0 0 0 0 0 0 0
				0 0 0 0 0 0 0 0 0 0 0 0 0 0 0 0 0 0
				0 0 0 0 0 0 0 0 0 0 0 0 0 0 0 0 0 0
				0 0 0 0 0 0 0 0 0 0 0 0 0 0 0 0 0 0
				0 0 0 0 0 0 0 0 0 0 0 0 0 0 0 0 0 0
				0 0 0 0 0 0 0 0 0 0 0 0 0 0 0 0 0 0
				0 0 0 0 0 0 0 0 0 0 0 0 0 0 0 0 0 0
				0 0 0 0 0 0 0 0 0 0 0 0 0 0 0 0 0 0
				0 0 0>;

			PS_Config_Lmt_FW_Diff_P = <
				50 50 50 50 50 50 50 50 50 50 50 50 50 50 50 50 50 50
				50 50 50 50 50 50 50 50 50 50 50 50 50 50 50 50 50 50
				50 50 50 50 50 50 50 50 50 50 50 50 50 50 50 50 50 50
				50 50 50 50 50 50 50 50 50 50 50 50 50 50 50 50 50 50
				50 50 50 50 50 50 50 50 50 50 50 50 50 50 50 50 50 50
				50 50 50 50 50 50 50 50 50 50 50 50 50 50 50 50 50 50
				50 50 50 50 50 50 50 50 50 50 50 50 50 50 50 50 50 50
				50 50 50 50 50 50 50 50 50 50 50 50 50 50 50 50 50 50
				50 50 50 50 50 50 50 50 50 50 50 50 50 50 50 50 50 50
				50 50 50 50 50 50 50 50 50 50 50 50 50 50 50 50 50 50
				50 50 50 50 50 50 50 50 50 50 50 50 50 50 50 50 50 50
				50 50 50 50 50 50 50 50 50 50 50 50 50 50 50 50 50 50
				50 50 50 50 50 50 50 50 50 50 50 50 50 50 50 50 50 50
				50 50 50 50 50 50 50 50 50 50 50 50 50 50 50 50 50 50
				50 50 50 50 50 50 50 50 50 50 50 50 50 50 50 50 50 50
				50 50 50 50 50 50 50 50 50 50 50 50 50 50 50 50 50 50
				50 50 50 50 50 50 50 50 50 50 50 50 50 50 50 50 50 50
				50 50 50 50 50 50 50 50 50 50 50 50 50 50 50 50 50 50
				50 50 50 50 50 50 50 50 50 50 50 50 50 50 50 50 50 50
				50 50 50 50 50 50 50 50 50 50 50 50 50 50 50 50 50 50
				50 50 50 50 50 50 50 50 50 50 50 50 50 50 50 50 50 50
				50 50 50 50 50 50 50 50 50 50 50 50 50 50 50 50 50 50
				50 50 50 50 50 50 50 50 50 50 50 50 50 50 50 50 50 50
				50 50 50 50 50 50 50 50 50 50 50 50 50 50 50 50 50 50
				50 50 50 50 50 50 50 50 50 50 50 50 50 50 50 50 50 50
				50 50 50 50 50 50 50 50 50 50 50 50 50 50 50 50 50 50
				50 50 50 50 50 50 50 50 50 50 50 50 50 50 50 50 50 50
				50 50 50 50 50 50 50 50 50 50 50 50 50 50 50 50 50 50
				50 50 50 50 50 50 50 50 50 50 50 50 50 50 50 50 50 50
				50 50 50 50 50 50 50 50 50 50 50 50 50 50 50 50 50 50
				50 50 50 50 50 50 50 50 50 50 50 50 50 50 50 50 50 50
				50 50 50 50 50 50 50 50 50 50 50 50 50 50 50 50 50 50
				50 50 50 50 50 50 50 50 50 50 50 50 50 50 50 50 50 50
				50 50 50 50 50 50 50 50 50 50 50 50 50 50 50 50 50 50
				50 50 50 50 50 50 50 50 50 50 50 50 50 50 50 50 50 50
				50 50 50 50 50 50 50 50 50 50 50 50 50 50 50 50 50 50
				50 50 50>;

			PS_Config_Lmt_FW_Diff_N = <
				(-50) (-50) (-50) (-50) (-50) (-50) (-50) (-50) (-50) (-50) (-50) (-50) (-50) (-50) (-50) (-50) (-50) (-50)
				(-50) (-50) (-50) (-50) (-50) (-50) (-50) (-50) (-50) (-50) (-50) (-50) (-50) (-50) (-50) (-50) (-50) (-50)
				(-50) (-50) (-50) (-50) (-50) (-50) (-50) (-50) (-50) (-50) (-50) (-50) (-50) (-50) (-50) (-50) (-50) (-50)
				(-50) (-50) (-50) (-50) (-50) (-50) (-50) (-50) (-50) (-50) (-50) (-50) (-50) (-50) (-50) (-50) (-50) (-50)
				(-50) (-50) (-50) (-50) (-50) (-50) (-50) (-50) (-50) (-50) (-50) (-50) (-50) (-50) (-50) (-50) (-50) (-50)
				(-50) (-50) (-50) (-50) (-50) (-50) (-50) (-50) (-50) (-50) (-50) (-50) (-50) (-50) (-50) (-50) (-50) (-50)
				(-50) (-50) (-50) (-50) (-50) (-50) (-50) (-50) (-50) (-50) (-50) (-50) (-50) (-50) (-50) (-50) (-50) (-50)
				(-50) (-50) (-50) (-50) (-50) (-50) (-50) (-50) (-50) (-50) (-50) (-50) (-50) (-50) (-50) (-50) (-50) (-50)
				(-50) (-50) (-50) (-50) (-50) (-50) (-50) (-50) (-50) (-50) (-50) (-50) (-50) (-50) (-50) (-50) (-50) (-50)
				(-50) (-50) (-50) (-50) (-50) (-50) (-50) (-50) (-50) (-50) (-50) (-50) (-50) (-50) (-50) (-50) (-50) (-50)
				(-50) (-50) (-50) (-50) (-50) (-50) (-50) (-50) (-50) (-50) (-50) (-50) (-50) (-50) (-50) (-50) (-50) (-50)
				(-50) (-50) (-50) (-50) (-50) (-50) (-50) (-50) (-50) (-50) (-50) (-50) (-50) (-50) (-50) (-50) (-50) (-50)
				(-50) (-50) (-50) (-50) (-50) (-50) (-50) (-50) (-50) (-50) (-50) (-50) (-50) (-50) (-50) (-50) (-50) (-50)
				(-50) (-50) (-50) (-50) (-50) (-50) (-50) (-50) (-50) (-50) (-50) (-50) (-50) (-50) (-50) (-50) (-50) (-50)
				(-50) (-50) (-50) (-50) (-50) (-50) (-50) (-50) (-50) (-50) (-50) (-50) (-50) (-50) (-50) (-50) (-50) (-50)
				(-50) (-50) (-50) (-50) (-50) (-50) (-50) (-50) (-50) (-50) (-50) (-50) (-50) (-50) (-50) (-50) (-50) (-50)
				(-50) (-50) (-50) (-50) (-50) (-50) (-50) (-50) (-50) (-50) (-50) (-50) (-50) (-50) (-50) (-50) (-50) (-50)
				(-50) (-50) (-50) (-50) (-50) (-50) (-50) (-50) (-50) (-50) (-50) (-50) (-50) (-50) (-50) (-50) (-50) (-50)
				(-50) (-50) (-50) (-50) (-50) (-50) (-50) (-50) (-50) (-50) (-50) (-50) (-50) (-50) (-50) (-50) (-50) (-50)
				(-50) (-50) (-50) (-50) (-50) (-50) (-50) (-50) (-50) (-50) (-50) (-50) (-50) (-50) (-50) (-50) (-50) (-50)
				(-50) (-50) (-50) (-50) (-50) (-50) (-50) (-50) (-50) (-50) (-50) (-50) (-50) (-50) (-50) (-50) (-50) (-50)
				(-50) (-50) (-50) (-50) (-50) (-50) (-50) (-50) (-50) (-50) (-50) (-50) (-50) (-50) (-50) (-50) (-50) (-50)
				(-50) (-50) (-50) (-50) (-50) (-50) (-50) (-50) (-50) (-50) (-50) (-50) (-50) (-50) (-50) (-50) (-50) (-50)
				(-50) (-50) (-50) (-50) (-50) (-50) (-50) (-50) (-50) (-50) (-50) (-50) (-50) (-50) (-50) (-50) (-50) (-50)
				(-50) (-50) (-50) (-50) (-50) (-50) (-50) (-50) (-50) (-50) (-50) (-50) (-50) (-50) (-50) (-50) (-50) (-50)
				(-50) (-50) (-50) (-50) (-50) (-50) (-50) (-50) (-50) (-50) (-50) (-50) (-50) (-50) (-50) (-50) (-50) (-50)
				(-50) (-50) (-50) (-50) (-50) (-50) (-50) (-50) (-50) (-50) (-50) (-50) (-50) (-50) (-50) (-50) (-50) (-50)
				(-50) (-50) (-50) (-50) (-50) (-50) (-50) (-50) (-50) (-50) (-50) (-50) (-50) (-50) (-50) (-50) (-50) (-50)
				(-50) (-50) (-50) (-50) (-50) (-50) (-50) (-50) (-50) (-50) (-50) (-50) (-50) (-50) (-50) (-50) (-50) (-50)
				(-50) (-50) (-50) (-50) (-50) (-50) (-50) (-50) (-50) (-50) (-50) (-50) (-50) (-50) (-50) (-50) (-50) (-50)
				(-50) (-50) (-50) (-50) (-50) (-50) (-50) (-50) (-50) (-50) (-50) (-50) (-50) (-50) (-50) (-50) (-50) (-50)
				(-50) (-50) (-50) (-50) (-50) (-50) (-50) (-50) (-50) (-50) (-50) (-50) (-50) (-50) (-50) (-50) (-50) (-50)
				(-50) (-50) (-50) (-50) (-50) (-50) (-50) (-50) (-50) (-50) (-50) (-50) (-50) (-50) (-50) (-50) (-50) (-50)
				(-50) (-50) (-50) (-50) (-50) (-50) (-50) (-50) (-50) (-50) (-50) (-50) (-50) (-50) (-50) (-50) (-50) (-50)
				(-50) (-50) (-50) (-50) (-50) (-50) (-50) (-50) (-50) (-50) (-50) (-50) (-50) (-50) (-50) (-50) (-50) (-50)
				(-50) (-50) (-50) (-50) (-50) (-50) (-50) (-50) (-50) (-50) (-50) (-50) (-50) (-50) (-50) (-50) (-50) (-50)
				(-50) (-50) (-50)>;

			PS_Config_Diff_Test_Frame = <50>;
		};

		/* for Xiaomi E7T 672A EBBG6.26" module */
		novatek-mp-criteria-590C@0 {
			#address-cells = <1>;
			#size-cells = <0>;
			compatible = "novatek-mp-criteria-590C";

			/* MP Config */
			IC_X_CFG_SIZE = <18>;
			IC_Y_CFG_SIZE = <36>;
			IC_KEY_CFG_SIZE = <4>;
			X_Channel = <18>;
			Y_Channel = <36>;
			  AIN_X = <0 1 2 3 4 5 6 7 8 9 10 11 12 13 14 15 16 17>;

			  AIN_Y = <0 1 2 3 4 5 6 7 8 9 10 11 12 13 14 15 16 17
							18 19 20 21 22 23 24 25 26 27 28 29 30 31 32 33 34 35>;

			AIN_KEY = <0 1 2 0xFF>;

			/* MP Criteria */
			PS_Config_Lmt_Short_Rawdata_P = <
				14000 14000 14000 14000 14000 14000 14000 14000 14000 14000 14000 14000 14000 14000 14000 14000 14000 14000
				14000 14000 14000 14000 14000 14000 14000 14000 14000 14000 14000 14000 14000 14000 14000 14000 14000 14000
				14000 14000 14000 14000 14000 14000 14000 14000 14000 14000 14000 14000 14000 14000 14000 14000 14000 14000
				14000 14000 14000 14000 14000 14000 14000 14000 14000 14000 14000 14000 14000 14000 14000 14000 14000 14000
				14000 14000 14000 14000 14000 14000 14000 14000 14000 14000 14000 14000 14000 14000 14000 14000 14000 14000
				14000 14000 14000 14000 14000 14000 14000 14000 14000 14000 14000 14000 14000 14000 14000 14000 14000 14000
				14000 14000 14000 14000 14000 14000 14000 14000 14000 14000 14000 14000 14000 14000 14000 14000 14000 14000
				14000 14000 14000 14000 14000 14000 14000 14000 14000 14000 14000 14000 14000 14000 14000 14000 14000 14000
				14000 14000 14000 14000 14000 14000 14000 14000 14000 14000 14000 14000 14000 14000 14000 14000 14000 14000
				14000 14000 14000 14000 14000 14000 14000 14000 14000 14000 14000 14000 14000 14000 14000 14000 14000 14000
				14000 14000 14000 14000 14000 14000 14000 14000 14000 14000 14000 14000 14000 14000 14000 14000 14000 14000
				14000 14000 14000 14000 14000 14000 14000 14000 14000 14000 14000 14000 14000 14000 14000 14000 14000 14000
				14000 14000 14000 14000 14000 14000 14000 14000 14000 14000 14000 14000 14000 14000 14000 14000 14000 14000
				14000 14000 14000 14000 14000 14000 14000 14000 14000 14000 14000 14000 14000 14000 14000 14000 14000 14000
				14000 14000 14000 14000 14000 14000 14000 14000 14000 14000 14000 14000 14000 14000 14000 14000 14000 14000
				14000 14000 14000 14000 14000 14000 14000 14000 14000 14000 14000 14000 14000 14000 14000 14000 14000 14000
				14000 14000 14000 14000 14000 14000 14000 14000 14000 14000 14000 14000 14000 14000 14000 14000 14000 14000
				14000 14000 14000 14000 14000 14000 14000 14000 14000 14000 14000 14000 14000 14000 14000 14000 14000 14000
				14000 14000 14000 14000 14000 14000 14000 14000 14000 14000 14000 14000 14000 14000 14000 14000 14000 14000
				14000 14000 14000 14000 14000 14000 14000 14000 14000 14000 14000 14000 14000 14000 14000 14000 14000 14000
				14000 14000 14000 14000 14000 14000 14000 14000 14000 14000 14000 14000 14000 14000 14000 14000 14000 14000
				14000 14000 14000 14000 14000 14000 14000 14000 14000 14000 14000 14000 14000 14000 14000 14000 14000 14000
				14000 14000 14000 14000 14000 14000 14000 14000 14000 14000 14000 14000 14000 14000 14000 14000 14000 14000
				14000 14000 14000 14000 14000 14000 14000 14000 14000 14000 14000 14000 14000 14000 14000 14000 14000 14000
				14000 14000 14000 14000 14000 14000 14000 14000 14000 14000 14000 14000 14000 14000 14000 14000 14000 14000
				14000 14000 14000 14000 14000 14000 14000 14000 14000 14000 14000 14000 14000 14000 14000 14000 14000 14000
				14000 14000 14000 14000 14000 14000 14000 14000 14000 14000 14000 14000 14000 14000 14000 14000 14000 14000
				14000 14000 14000 14000 14000 14000 14000 14000 14000 14000 14000 14000 14000 14000 14000 14000 14000 14000
				14000 14000 14000 14000 14000 14000 14000 14000 14000 14000 14000 14000 14000 14000 14000 14000 14000 14000
				14000 14000 14000 14000 14000 14000 14000 14000 14000 14000 14000 14000 14000 14000 14000 14000 14000 14000
				14000 14000 14000 14000 14000 14000 14000 14000 14000 14000 14000 14000 14000 14000 14000 14000 14000 14000
				14000 14000 14000 14000 14000 14000 14000 14000 14000 14000 14000 14000 14000 14000 14000 14000 14000 14000
				14000 14000 14000 14000 14000 14000 14000 14000 14000 14000 14000 14000 14000 14000 14000 14000 14000 14000
				14000 14000 14000 14000 14000 14000 14000 14000 14000 14000 14000 14000 14000 14000 14000 14000 14000 14000
				14000 14000 14000 14000 14000 14000 14000 14000 14000 14000 14000 14000 14000 14000 14000 14000 14000 14000
				14000 14000 14000 14000 14000 14000 14000 14000 14000 14000 14000 14000 14000 14000 14000 14000 14000 14000
				20000 20000 20000>;

			PS_Config_Lmt_Short_Rawdata_N = <
				11000 11000 11000 11000 11000 11000 11000 11000 11000 11000 11000 11000 11000 11000 11000 11000 11000 11000
				11000 11000 11000 11000 11000 11000 11000 11000 11000 11000 11000 11000 11000 11000 11000 11000 11000 11000
				11000 11000 11000 11000 11000 11000 11000 11000 11000 11000 11000 11000 11000 11000 11000 11000 11000 11000
				11000 11000 11000 11000 11000 11000 11000 11000 11000 11000 11000 11000 11000 11000 11000 11000 11000 11000
				11000 11000 11000 11000 11000 11000 11000 11000 11000 11000 11000 11000 11000 11000 11000 11000 11000 11000
				11000 11000 11000 11000 11000 11000 11000 11000 11000 11000 11000 11000 11000 11000 11000 11000 11000 11000
				11000 11000 11000 11000 11000 11000 11000 11000 11000 11000 11000 11000 11000 11000 11000 11000 11000 11000
				11000 11000 11000 11000 11000 11000 11000 11000 11000 11000 11000 11000 11000 11000 11000 11000 11000 11000
				11000 11000 11000 11000 11000 11000 11000 11000 11000 11000 11000 11000 11000 11000 11000 11000 11000 11000
				11000 11000 11000 11000 11000 11000 11000 11000 11000 11000 11000 11000 11000 11000 11000 11000 11000 11000
				11000 11000 11000 11000 11000 11000 11000 11000 11000 11000 11000 11000 11000 11000 11000 11000 11000 11000
				11000 11000 11000 11000 11000 11000 11000 11000 11000 11000 11000 11000 11000 11000 11000 11000 11000 11000
				11000 11000 11000 11000 11000 11000 11000 11000 11000 11000 11000 11000 11000 11000 11000 11000 11000 11000
				11000 11000 11000 11000 11000 11000 11000 11000 11000 11000 11000 11000 11000 11000 11000 11000 11000 11000
				11000 11000 11000 11000 11000 11000 11000 11000 11000 11000 11000 11000 11000 11000 11000 11000 11000 11000
				11000 11000 11000 11000 11000 11000 11000 11000 11000 11000 11000 11000 11000 11000 11000 11000 11000 11000
				11000 11000 11000 11000 11000 11000 11000 11000 11000 11000 11000 11000 11000 11000 11000 11000 11000 11000
				11000 11000 11000 11000 11000 11000 11000 11000 11000 11000 11000 11000 11000 11000 11000 11000 11000 11000
				11000 11000 11000 11000 11000 11000 11000 11000 11000 11000 11000 11000 11000 11000 11000 11000 11000 11000
				11000 11000 11000 11000 11000 11000 11000 11000 11000 11000 11000 11000 11000 11000 11000 11000 11000 11000
				11000 11000 11000 11000 11000 11000 11000 11000 11000 11000 11000 11000 11000 11000 11000 11000 11000 11000
				11000 11000 11000 11000 11000 11000 11000 11000 11000 11000 11000 11000 11000 11000 11000 11000 11000 11000
				11000 11000 11000 11000 11000 11000 11000 11000 11000 11000 11000 11000 11000 11000 11000 11000 11000 11000
				11000 11000 11000 11000 11000 11000 11000 11000 11000 11000 11000 11000 11000 11000 11000 11000 11000 11000
				11000 11000 11000 11000 11000 11000 11000 11000 11000 11000 11000 11000 11000 11000 11000 11000 11000 11000
				11000 11000 11000 11000 11000 11000 11000 11000 11000 11000 11000 11000 11000 11000 11000 11000 11000 11000
				11000 11000 11000 11000 11000 11000 11000 11000 11000 11000 11000 11000 11000 11000 11000 11000 11000 11000
				11000 11000 11000 11000 11000 11000 11000 11000 11000 11000 11000 11000 11000 11000 11000 11000 11000 11000
				11000 11000 11000 11000 11000 11000 11000 11000 11000 11000 11000 11000 11000 11000 11000 11000 11000 11000
				11000 11000 11000 11000 11000 11000 11000 11000 11000 11000 11000 11000 11000 11000 11000 11000 11000 11000
				11000 11000 11000 11000 11000 11000 11000 11000 11000 11000 11000 11000 11000 11000 11000 11000 11000 11000
				11000 11000 11000 11000 11000 11000 11000 11000 11000 11000 11000 11000 11000 11000 11000 11000 11000 11000
				11000 11000 11000 11000 11000 11000 11000 11000 11000 11000 11000 11000 11000 11000 11000 11000 11000 11000
				11000 11000 11000 11000 11000 11000 11000 11000 11000 11000 11000 11000 11000 11000 11000 11000 11000 11000
				11000 11000 11000 11000 11000 11000 11000 11000 11000 11000 11000 11000 11000 11000 11000 11000 11000 11000
				11000 11000 11000 11000 11000 11000 11000 11000 11000 11000 11000 11000 11000 11000 11000 11000 11000 11000
				11550 11550 11550>;

			PS_Config_Lmt_Short_Diff_P = <
				6300 6300 6300 6300 6300 6300 6300 6300 6300 6300 6300 6300 6300 6300 6300 6300 6300 6300
				6300 6300 6300 6300 6300 6300 6300 6300 6300 6300 6300 6300 6300 6300 6300 6300 6300 6300
				6300 6300 6300 6300 6300 6300 6300 6300 6300 6300 6300 6300 6300 6300 6300 6300 6300 6300
				6300 6300 6300 6300 6300 6300 6300 6300 6300 6300 6300 6300 6300 6300 6300 6300 6300 6300
				6300 6300 6300 6300 6300 6300 6300 6300 6300 6300 6300 6300 6300 6300 6300 6300 6300 6300
				6300 6300 6300 6300 6300 6300 6300 6300 6300 6300 6300 6300 6300 6300 6300 6300 6300 6300
				6300 6300 6300 6300 6300 6300 6300 6300 6300 6300 6300 6300 6300 6300 6300 6300 6300 6300
				6300 6300 6300 6300 6300 6300 6300 6300 6300 6300 6300 6300 6300 6300 6300 6300 6300 6300
				6300 6300 6300 6300 6300 6300 6300 6300 6300 6300 6300 6300 6300 6300 6300 6300 6300 6300
				6300 6300 6300 6300 6300 6300 6300 6300 6300 6300 6300 6300 6300 6300 6300 6300 6300 6300
				6300 6300 6300 6300 6300 6300 6300 6300 6300 6300 6300 6300 6300 6300 6300 6300 6300 6300
				6300 6300 6300 6300 6300 6300 6300 6300 6300 6300 6300 6300 6300 6300 6300 6300 6300 6300
				6300 6300 6300 6300 6300 6300 6300 6300 6300 6300 6300 6300 6300 6300 6300 6300 6300 6300
				6300 6300 6300 6300 6300 6300 6300 6300 6300 6300 6300 6300 6300 6300 6300 6300 6300 6300
				6300 6300 6300 6300 6300 6300 6300 6300 6300 6300 6300 6300 6300 6300 6300 6300 6300 6300
				6300 6300 6300 6300 6300 6300 6300 6300 6300 6300 6300 6300 6300 6300 6300 6300 6300 6300
				6300 6300 6300 6300 6300 6300 6300 6300 6300 6300 6300 6300 6300 6300 6300 6300 6300 6300
				6300 6300 6300 6300 6300 6300 6300 6300 6300 6300 6300 6300 6300 6300 6300 6300 6300 6300
				6300 6300 6300 6300 6300 6300 6300 6300 6300 6300 6300 6300 6300 6300 6300 6300 6300 6300
				6300 6300 6300 6300 6300 6300 6300 6300 6300 6300 6300 6300 6300 6300 6300 6300 6300 6300
				6300 6300 6300 6300 6300 6300 6300 6300 6300 6300 6300 6300 6300 6300 6300 6300 6300 6300
				6300 6300 6300 6300 6300 6300 6300 6300 6300 6300 6300 6300 6300 6300 6300 6300 6300 6300
				6300 6300 6300 6300 6300 6300 6300 6300 6300 6300 6300 6300 6300 6300 6300 6300 6300 6300
				6300 6300 6300 6300 6300 6300 6300 6300 6300 6300 6300 6300 6300 6300 6300 6300 6300 6300
				6300 6300 6300 6300 6300 6300 6300 6300 6300 6300 6300 6300 6300 6300 6300 6300 6300 6300
				6300 6300 6300 6300 6300 6300 6300 6300 6300 6300 6300 6300 6300 6300 6300 6300 6300 6300
				6300 6300 6300 6300 6300 6300 6300 6300 6300 6300 6300 6300 6300 6300 6300 6300 6300 6300
				6300 6300 6300 6300 6300 6300 6300 6300 6300 6300 6300 6300 6300 6300 6300 6300 6300 6300
				6300 6300 6300 6300 6300 6300 6300 6300 6300 6300 6300 6300 6300 6300 6300 6300 6300 6300
				6300 6300 6300 6300 6300 6300 6300 6300 6300 6300 6300 6300 6300 6300 6300 6300 6300 6300
				6300 6300 6300 6300 6300 6300 6300 6300 6300 6300 6300 6300 6300 6300 6300 6300 6300 6300
				6300 6300 6300 6300 6300 6300 6300 6300 6300 6300 6300 6300 6300 6300 6300 6300 6300 6300
				6300 6300 6300>;

			PS_Config_Lmt_Short_Diff_N = <
				0 0 0 0 0 0 0 0 0 0 0 0 0 0 0 0 0 0
				0 0 0 0 0 0 0 0 0 0 0 0 0 0 0 0 0 0
				0 0 0 0 0 0 0 0 0 0 0 0 0 0 0 0 0 0
				0 0 0 0 0 0 0 0 0 0 0 0 0 0 0 0 0 0
				0 0 0 0 0 0 0 0 0 0 0 0 0 0 0 0 0 0
				0 0 0 0 0 0 0 0 0 0 0 0 0 0 0 0 0 0
				0 0 0 0 0 0 0 0 0 0 0 0 0 0 0 0 0 0
				0 0 0 0 0 0 0 0 0 0 0 0 0 0 0 0 0 0
				0 0 0 0 0 0 0 0 0 0 0 0 0 0 0 0 0 0
				0 0 0 0 0 0 0 0 0 0 0 0 0 0 0 0 0 0
				0 0 0 0 0 0 0 0 0 0 0 0 0 0 0 0 0 0
				0 0 0 0 0 0 0 0 0 0 0 0 0 0 0 0 0 0
				0 0 0 0 0 0 0 0 0 0 0 0 0 0 0 0 0 0
				0 0 0 0 0 0 0 0 0 0 0 0 0 0 0 0 0 0
				0 0 0 0 0 0 0 0 0 0 0 0 0 0 0 0 0 0
				0 0 0 0 0 0 0 0 0 0 0 0 0 0 0 0 0 0
				0 0 0 0 0 0 0 0 0 0 0 0 0 0 0 0 0 0
				0 0 0 0 0 0 0 0 0 0 0 0 0 0 0 0 0 0
				0 0 0 0 0 0 0 0 0 0 0 0 0 0 0 0 0 0
				0 0 0 0 0 0 0 0 0 0 0 0 0 0 0 0 0 0
				0 0 0 0 0 0 0 0 0 0 0 0 0 0 0 0 0 0
				0 0 0 0 0 0 0 0 0 0 0 0 0 0 0 0 0 0
				0 0 0 0 0 0 0 0 0 0 0 0 0 0 0 0 0 0
				0 0 0 0 0 0 0 0 0 0 0 0 0 0 0 0 0 0
				0 0 0 0 0 0 0 0 0 0 0 0 0 0 0 0 0 0
				0 0 0 0 0 0 0 0 0 0 0 0 0 0 0 0 0 0
				0 0 0 0 0 0 0 0 0 0 0 0 0 0 0 0 0 0
				0 0 0 0 0 0 0 0 0 0 0 0 0 0 0 0 0 0
				0 0 0 0 0 0 0 0 0 0 0 0 0 0 0 0 0 0
				0 0 0 0 0 0 0 0 0 0 0 0 0 0 0 0 0 0
				0 0 0 0 0 0 0 0 0 0 0 0 0 0 0 0 0 0
				0 0 0 0 0 0 0 0 0 0 0 0 0 0 0 0 0 0
				0 0 0>;

			PS_Config_Lmt_Short_Base_P = <
				2000 2000 2000 2000 2000 2000 2000 2000 2000 2000 2000 2000 2000 2000 2000 2000 2000 2000
				2000 2000 2000 2000 2000 2000 2000 2000 2000 2000 2000 2000 2000 2000 2000 2000 2000 2000
				2000 2000 2000 2000 2000 2000 2000 2000 2000 2000 2000 2000 2000 2000 2000 2000 2000 2000
				2000 2000 2000 2000 2000 2000 2000 2000 2000 2000 2000 2000 2000 2000 2000 2000 2000 2000
				2000 2000 2000 2000 2000 2000 2000 2000 2000 2000 2000 2000 2000 2000 2000 2000 2000 2000
				2000 2000 2000 2000 2000 2000 2000 2000 2000 2000 2000 2000 2000 2000 2000 2000 2000 2000
				2000 2000 2000 2000 2000 2000 2000 2000 2000 2000 2000 2000 2000 2000 2000 2000 2000 2000
				2000 2000 2000 2000 2000 2000 2000 2000 2000 2000 2000 2000 2000 2000 2000 2000 2000 2000
				2000 2000 2000 2000 2000 2000 2000 2000 2000 2000 2000 2000 2000 2000 2000 2000 2000 2000
				2000 2000 2000 2000 2000 2000 2000 2000 2000 2000 2000 2000 2000 2000 2000 2000 2000 2000
				2000 2000 2000 2000 2000 2000 2000 2000 2000 2000 2000 2000 2000 2000 2000 2000 2000 2000
				2000 2000 2000 2000 2000 2000 2000 2000 2000 2000 2000 2000 2000 2000 2000 2000 2000 2000
				2000 2000 2000 2000 2000 2000 2000 2000 2000 2000 2000 2000 2000 2000 2000 2000 2000 2000
				2000 2000 2000 2000 2000 2000 2000 2000 2000 2000 2000 2000 2000 2000 2000 2000 2000 2000
				2000 2000 2000 2000 2000 2000 2000 2000 2000 2000 2000 2000 2000 2000 2000 2000 2000 2000
				2000 2000 2000 2000 2000 2000 2000 2000 2000 2000 2000 2000 2000 2000 2000 2000 2000 2000
				2000 2000 2000 2000 2000 2000 2000 2000 2000 2000 2000 2000 2000 2000 2000 2000 2000 2000
				2000 2000 2000 2000 2000 2000 2000 2000 2000 2000 2000 2000 2000 2000 2000 2000 2000 2000
				2000 2000 2000 2000 2000 2000 2000 2000 2000 2000 2000 2000 2000 2000 2000 2000 2000 2000
				2000 2000 2000 2000 2000 2000 2000 2000 2000 2000 2000 2000 2000 2000 2000 2000 2000 2000
				2000 2000 2000 2000 2000 2000 2000 2000 2000 2000 2000 2000 2000 2000 2000 2000 2000 2000
				2000 2000 2000 2000 2000 2000 2000 2000 2000 2000 2000 2000 2000 2000 2000 2000 2000 2000
				2000 2000 2000 2000 2000 2000 2000 2000 2000 2000 2000 2000 2000 2000 2000 2000 2000 2000
				2000 2000 2000 2000 2000 2000 2000 2000 2000 2000 2000 2000 2000 2000 2000 2000 2000 2000
				2000 2000 2000 2000 2000 2000 2000 2000 2000 2000 2000 2000 2000 2000 2000 2000 2000 2000
				2000 2000 2000 2000 2000 2000 2000 2000 2000 2000 2000 2000 2000 2000 2000 2000 2000 2000
				2000 2000 2000 2000 2000 2000 2000 2000 2000 2000 2000 2000 2000 2000 2000 2000 2000 2000
				2000 2000 2000 2000 2000 2000 2000 2000 2000 2000 2000 2000 2000 2000 2000 2000 2000 2000
				2000 2000 2000 2000 2000 2000 2000 2000 2000 2000 2000 2000 2000 2000 2000 2000 2000 2000
				2000 2000 2000 2000 2000 2000 2000 2000 2000 2000 2000 2000 2000 2000 2000 2000 2000 2000
				2000 2000 2000 2000 2000 2000 2000 2000 2000 2000 2000 2000 2000 2000 2000 2000 2000 2000
				2000 2000 2000 2000 2000 2000 2000 2000 2000 2000 2000 2000 2000 2000 2000 2000 2000 2000
				2000 2000 2000>;

			PS_Config_Lmt_Short_Base_N = <
				(-2000) (-2000) (-2000) (-2000) (-2000) (-2000) (-2000) (-2000) (-2000) (-2000) (-2000) (-2000) (-2000) (-2000) (-2000) (-2000) (-2000) (-2000)
				(-2000) (-2000) (-2000) (-2000) (-2000) (-2000) (-2000) (-2000) (-2000) (-2000) (-2000) (-2000) (-2000) (-2000) (-2000) (-2000) (-2000) (-2000)
				(-2000) (-2000) (-2000) (-2000) (-2000) (-2000) (-2000) (-2000) (-2000) (-2000) (-2000) (-2000) (-2000) (-2000) (-2000) (-2000) (-2000) (-2000)
				(-2000) (-2000) (-2000) (-2000) (-2000) (-2000) (-2000) (-2000) (-2000) (-2000) (-2000) (-2000) (-2000) (-2000) (-2000) (-2000) (-2000) (-2000)
				(-2000) (-2000) (-2000) (-2000) (-2000) (-2000) (-2000) (-2000) (-2000) (-2000) (-2000) (-2000) (-2000) (-2000) (-2000) (-2000) (-2000) (-2000)
				(-2000) (-2000) (-2000) (-2000) (-2000) (-2000) (-2000) (-2000) (-2000) (-2000) (-2000) (-2000) (-2000) (-2000) (-2000) (-2000) (-2000) (-2000)
				(-2000) (-2000) (-2000) (-2000) (-2000) (-2000) (-2000) (-2000) (-2000) (-2000) (-2000) (-2000) (-2000) (-2000) (-2000) (-2000) (-2000) (-2000)
				(-2000) (-2000) (-2000) (-2000) (-2000) (-2000) (-2000) (-2000) (-2000) (-2000) (-2000) (-2000) (-2000) (-2000) (-2000) (-2000) (-2000) (-2000)
				(-2000) (-2000) (-2000) (-2000) (-2000) (-2000) (-2000) (-2000) (-2000) (-2000) (-2000) (-2000) (-2000) (-2000) (-2000) (-2000) (-2000) (-2000)
				(-2000) (-2000) (-2000) (-2000) (-2000) (-2000) (-2000) (-2000) (-2000) (-2000) (-2000) (-2000) (-2000) (-2000) (-2000) (-2000) (-2000) (-2000)
				(-2000) (-2000) (-2000) (-2000) (-2000) (-2000) (-2000) (-2000) (-2000) (-2000) (-2000) (-2000) (-2000) (-2000) (-2000) (-2000) (-2000) (-2000)
				(-2000) (-2000) (-2000) (-2000) (-2000) (-2000) (-2000) (-2000) (-2000) (-2000) (-2000) (-2000) (-2000) (-2000) (-2000) (-2000) (-2000) (-2000)
				(-2000) (-2000) (-2000) (-2000) (-2000) (-2000) (-2000) (-2000) (-2000) (-2000) (-2000) (-2000) (-2000) (-2000) (-2000) (-2000) (-2000) (-2000)
				(-2000) (-2000) (-2000) (-2000) (-2000) (-2000) (-2000) (-2000) (-2000) (-2000) (-2000) (-2000) (-2000) (-2000) (-2000) (-2000) (-2000) (-2000)
				(-2000) (-2000) (-2000) (-2000) (-2000) (-2000) (-2000) (-2000) (-2000) (-2000) (-2000) (-2000) (-2000) (-2000) (-2000) (-2000) (-2000) (-2000)
				(-2000) (-2000) (-2000) (-2000) (-2000) (-2000) (-2000) (-2000) (-2000) (-2000) (-2000) (-2000) (-2000) (-2000) (-2000) (-2000) (-2000) (-2000)
				(-2000) (-2000) (-2000) (-2000) (-2000) (-2000) (-2000) (-2000) (-2000) (-2000) (-2000) (-2000) (-2000) (-2000) (-2000) (-2000) (-2000) (-2000)
				(-2000) (-2000) (-2000) (-2000) (-2000) (-2000) (-2000) (-2000) (-2000) (-2000) (-2000) (-2000) (-2000) (-2000) (-2000) (-2000) (-2000) (-2000)
				(-2000) (-2000) (-2000) (-2000) (-2000) (-2000) (-2000) (-2000) (-2000) (-2000) (-2000) (-2000) (-2000) (-2000) (-2000) (-2000) (-2000) (-2000)
				(-2000) (-2000) (-2000) (-2000) (-2000) (-2000) (-2000) (-2000) (-2000) (-2000) (-2000) (-2000) (-2000) (-2000) (-2000) (-2000) (-2000) (-2000)
				(-2000) (-2000) (-2000) (-2000) (-2000) (-2000) (-2000) (-2000) (-2000) (-2000) (-2000) (-2000) (-2000) (-2000) (-2000) (-2000) (-2000) (-2000)
				(-2000) (-2000) (-2000) (-2000) (-2000) (-2000) (-2000) (-2000) (-2000) (-2000) (-2000) (-2000) (-2000) (-2000) (-2000) (-2000) (-2000) (-2000)
				(-2000) (-2000) (-2000) (-2000) (-2000) (-2000) (-2000) (-2000) (-2000) (-2000) (-2000) (-2000) (-2000) (-2000) (-2000) (-2000) (-2000) (-2000)
				(-2000) (-2000) (-2000) (-2000) (-2000) (-2000) (-2000) (-2000) (-2000) (-2000) (-2000) (-2000) (-2000) (-2000) (-2000) (-2000) (-2000) (-2000)
				(-2000) (-2000) (-2000) (-2000) (-2000) (-2000) (-2000) (-2000) (-2000) (-2000) (-2000) (-2000) (-2000) (-2000) (-2000) (-2000) (-2000) (-2000)
				(-2000) (-2000) (-2000) (-2000) (-2000) (-2000) (-2000) (-2000) (-2000) (-2000) (-2000) (-2000) (-2000) (-2000) (-2000) (-2000) (-2000) (-2000)
				(-2000) (-2000) (-2000) (-2000) (-2000) (-2000) (-2000) (-2000) (-2000) (-2000) (-2000) (-2000) (-2000) (-2000) (-2000) (-2000) (-2000) (-2000)
				(-2000) (-2000) (-2000) (-2000) (-2000) (-2000) (-2000) (-2000) (-2000) (-2000) (-2000) (-2000) (-2000) (-2000) (-2000) (-2000) (-2000) (-2000)
				(-2000) (-2000) (-2000) (-2000) (-2000) (-2000) (-2000) (-2000) (-2000) (-2000) (-2000) (-2000) (-2000) (-2000) (-2000) (-2000) (-2000) (-2000)
				(-2000) (-2000) (-2000) (-2000) (-2000) (-2000) (-2000) (-2000) (-2000) (-2000) (-2000) (-2000) (-2000) (-2000) (-2000) (-2000) (-2000) (-2000)
				(-2000) (-2000) (-2000) (-2000) (-2000) (-2000) (-2000) (-2000) (-2000) (-2000) (-2000) (-2000) (-2000) (-2000) (-2000) (-2000) (-2000) (-2000)
				(-2000) (-2000) (-2000) (-2000) (-2000) (-2000) (-2000) (-2000) (-2000) (-2000) (-2000) (-2000) (-2000) (-2000) (-2000) (-2000) (-2000) (-2000)
				(-2000) (-2000) (-2000)>;

			PS_Config_Lmt_Open_Rawdata_P = <
				65535 4349 4424 4709 4486 65535 65535 65535 65535 65535 65535 65535 65535 4469 4695 4394 4260 65535
				1748 1943 1765 1835 1645 1351 1300 1324 1297 1285 1305 1285 1328 1626 1808 1750 1927 1738
				1654 1814 1661 1710 1621 1680 1615 1678 1615 1611 1668 1609 1667 1614 1696 1654 1814 1656
				1620 1764 1617 1658 1581 1631 1574 1631 1576 1570 1620 1568 1616 1572 1643 1612 1765 1621
				1666 1807 1656 1700 1617 1672 1612 1673 1614 1604 1657 1600 1652 1605 1681 1644 1800 1659
				1623 1747 1604 1640 1567 1614 1562 1615 1563 1558 1602 1553 1596 1557 1623 1597 1741 1620
				1662 1691 1639 1677 1601 1649 1597 1652 1597 1601 1652 1596 1645 1600 1673 1640 1706 1668
				1617 1631 1591 1621 1554 1595 1549 1597 1550 1541 1583 1539 1578 1539 1604 1578 1631 1614
				1658 1672 1628 1663 1590 1635 1588 1640 1586 1584 1626 1579 1620 1579 1649 1619 1677 1658
				1619 1619 1583 1611 1545 1583 1545 1588 1543 1526 1562 1524 1557 1524 1586 1562 1610 1604
				1649 1746 1692 1736 1568 1610 1570 1616 1569 1567 1606 1563 1600 1560 1732 1686 1756 1649
				1601 1687 1643 1680 1517 1554 1520 1559 1520 1518 1545 1510 1541 1507 1673 1634 1694 1597
				1630 1719 1671 1711 1544 1584 1546 1591 1546 1554 1586 1544 1578 1540 1711 1666 1727 1633
				1591 1667 1624 1659 1498 1535 1503 1543 1502 1494 1518 1484 1512 1479 1640 1604 1657 1574
				1617 1696 1651 1682 1522 1559 1527 1563 1524 1531 1555 1522 1555 1517 1685 1643 1704 1615
				1572 1640 1601 1628 1474 1506 1479 1511 1478 1477 1494 1468 1493 1461 1621 1588 1638 1562
				1601 1671 1629 1658 1501 1536 1506 1540 1503 1501 1527 1492 1518 1484 1648 1612 1663 1588
				1550 1609 1572 1597 1445 1475 1452 1475 1449 1450 1465 1442 1464 1435 1590 1563 1604 1541
				1572 1628 1591 1616 1463 1493 1470 1492 1465 1474 1492 1465 1490 1459 1617 1587 1633 1569
				1510 1558 1527 1545 1402 1426 1407 1426 1410 1418 1430 1408 1427 1402 1554 1530 1564 1513
				1537 1586 1553 1573 1424 1452 1432 1450 1432 1436 1445 1424 1449 1419 1573 1546 1582 1532
				1484 1526 1498 1513 1372 1397 1380 1394 1377 1385 1388 1374 1393 1369 1516 1494 1520 1480
				1499 1540 1513 1527 1386 1409 1393 1405 1390 1407 1414 1397 1417 1389 1541 1516 1544 1502
				1445 1477 1456 1465 1330 1351 1338 1348 1334 1348 1351 1339 1352 1330 1473 1456 1475 1443
				1389 1438 1394 1421 1315 1355 1323 1353 1319 1328 1352 1318 1355 1313 1426 1390 1431 1384
				1341 1381 1346 1365 1266 1300 1275 1301 1270 1268 1290 1262 1291 1256 1360 1333 1365 1324
				1350 1390 1356 1374 1275 1306 1283 1309 1275 1281 1308 1276 1306 1268 1375 1344 1379 1338
				1292 1324 1296 1309 1217 1240 1226 1249 1217 1216 1245 1220 1239 1211 1310 1289 1314 1280
				1308 1341 1311 1324 1233 1256 1242 1257 1233 1225 1252 1228 1247 1220 1322 1297 1323 1287
				1247 1273 1252 1258 1173 1189 1179 1191 1170 1160 1183 1167 1178 1159 1250 1234 1252 1224
				1250 1275 1254 1259 1177 1191 1183 1192 1173 1172 1195 1177 1191 1170 1264 1247 1267 1238
				1200 1220 1206 1209 1127 1139 1136 1143 1126 1116 1135 1123 1130 1116 1203 1191 1205 1182
				1202 1224 1209 1210 1130 1140 1139 1144 1127 1121 1139 1127 1135 1120 1209 1196 1210 1186
				1150 1165 1155 1154 1078 1085 1087 1092 1075 1064 1079 1070 1074 1064 1149 1139 1148 1129
				1145 1167 1153 1151 1075 1080 1084 1085 1071 1075 1093 1084 1087 1076 1163 1153 1167 1141
				1794 1023 1189 1189 1112 1118 1121 1122 1111 1115 1130 1122 1125 1115 1198 1188 1024 1746
				13000 13000 13000>;

			PS_Config_Lmt_Open_Rawdata_N = <
				0 2500 2543 2706 2579 0 0 0 0 0 0 0 0 2568 2698 2525 2449 0
				1005 1116 1014 1054 946 776 747 761 746 738 750 738 763 935 1039 1005 1108 999
				951 1043 954 983 932 965 928 965 928 926 959 924 958 927 975 951 1043 951
				931 1013 930 953 908 938 905 938 905 903 931 901 929 903 944 927 1014 932
				957 1038 951 977 930 961 927 962 927 921 952 919 949 922 966 945 1035 954
				932 1004 921 943 900 927 897 928 898 895 921 892 917 894 932 918 1000 931
				955 972 942 964 920 948 918 949 918 920 949 917 946 919 962 943 981 959
				930 938 914 932 893 916 890 918 891 886 910 884 907 884 921 907 938 927
				953 961 935 956 913 940 913 943 911 911 935 908 931 908 948 930 964 953
				930 930 910 926 888 910 888 913 886 877 897 876 894 876 911 897 925 921
				948 1003 973 997 901 925 903 929 902 900 923 898 919 897 995 969 1009 948
				920 970 944 965 872 893 873 896 873 873 888 867 886 866 962 939 973 918
				937 988 960 984 887 911 889 914 889 893 911 887 907 885 984 957 992 938
				914 958 933 954 861 882 864 886 863 859 873 853 869 850 943 921 952 905
				930 975 949 967 875 896 878 898 876 880 894 875 894 872 968 944 979 928
				903 943 920 935 847 865 850 868 849 848 859 843 858 840 932 913 941 897
				920 960 936 953 862 883 865 885 864 862 878 857 873 853 947 927 956 913
				891 924 903 918 830 848 835 848 832 833 842 829 841 824 913 898 921 886
				903 935 914 929 840 858 845 857 842 847 857 842 857 838 930 912 938 902
				867 895 878 888 805 819 808 819 811 815 821 809 820 805 893 879 899 870
				884 911 892 904 819 835 823 833 823 825 830 819 832 816 904 889 909 881
				853 877 861 870 789 803 793 801 792 796 797 789 800 786 871 859 873 851
				862 885 870 878 797 810 800 808 799 808 813 803 814 798 886 871 887 863
				830 848 837 842 765 776 769 775 767 775 776 770 777 765 846 837 848 830
				798 827 801 816 756 778 760 778 758 763 777 757 778 754 819 799 822 795
				770 794 773 784 727 747 732 748 730 729 741 725 742 721 781 766 784 761
				775 799 779 789 732 751 738 752 732 736 751 733 751 729 790 773 792 769
				743 761 745 752 700 713 705 718 700 699 716 701 712 696 753 740 755 735
				751 770 754 761 708 721 713 722 708 704 719 705 716 701 759 746 760 740
				716 732 719 723 674 684 678 684 673 667 680 670 677 666 719 709 719 703
				719 732 721 724 676 684 680 685 674 673 686 676 684 673 727 716 728 711
				689 701 693 694 648 654 653 657 647 641 652 646 649 641 692 684 692 679
				691 703 694 695 649 655 654 657 648 644 654 648 652 643 694 687 695 681
				661 670 664 663 619 624 624 627 618 611 620 615 617 611 660 654 659 648
				658 670 662 662 618 621 623 624 616 618 628 623 624 619 668 662 670 656
				1031 588 684 684 639 643 644 645 638 640 649 645 646 640 689 683 589 1003
				6500 6500 6500>;

			PS_Config_Lmt_FW_Rawdata_P = <
				65535 1750 1750 1750 1750 65535 65535 65535 65535 65535 65535 65535 65535 1750 1750 1750 1750 65535
				1750 1750 1750 1750 1750 1750 1750 1750 1750 1750 1750 1750 1750 1750 1750 1750 1750 1750
				1750 1750 1750 1750 1750 1750 1750 1750 1750 1750 1750 1750 1750 1750 1750 1750 1750 1750
				1750 1750 1750 1750 1750 1750 1750 1750 1750 1750 1750 1750 1750 1750 1750 1750 1750 1750
				1750 1750 1750 1750 1750 1750 1750 1750 1750 1750 1750 1750 1750 1750 1750 1750 1750 1750
				1750 1750 1750 1750 1750 1750 1750 1750 1750 1750 1750 1750 1750 1750 1750 1750 1750 1750
				1750 1750 1750 1750 1750 1750 1750 1750 1750 1750 1750 1750 1750 1750 1750 1750 1750 1750
				1750 1750 1750 1750 1750 1750 1750 1750 1750 1750 1750 1750 1750 1750 1750 1750 1750 1750
				1750 1750 1750 1750 1750 1750 1750 1750 1750 1750 1750 1750 1750 1750 1750 1750 1750 1750
				1750 1750 1750 1750 1750 1750 1750 1750 1750 1750 1750 1750 1750 1750 1750 1750 1750 1750
				1750 1750 1750 1750 1750 1750 1750 1750 1750 1750 1750 1750 1750 1750 1750 1750 1750 1750
				1750 1750 1750 1750 1750 1750 1750 1750 1750 1750 1750 1750 1750 1750 1750 1750 1750 1750
				1750 1750 1750 1750 1750 1750 1750 1750 1750 1750 1750 1750 1750 1750 1750 1750 1750 1750
				1750 1750 1750 1750 1750 1750 1750 1750 1750 1750 1750 1750 1750 1750 1750 1750 1750 1750
				1750 1750 1750 1750 1750 1750 1750 1750 1750 1750 1750 1750 1750 1750 1750 1750 1750 1750
				1750 1750 1750 1750 1750 1750 1750 1750 1750 1750 1750 1750 1750 1750 1750 1750 1750 1750
				1750 1750 1750 1750 1750 1750 1750 1750 1750 1750 1750 1750 1750 1750 1750 1750 1750 1750
				1750 1750 1750 1750 1750 1750 1750 1750 1750 1750 1750 1750 1750 1750 1750 1750 1750 1750
				1750 1750 1750 1750 1750 1750 1750 1750 1750 1750 1750 1750 1750 1750 1750 1750 1750 1750
				1750 1750 1750 1750 1750 1750 1750 1750 1750 1750 1750 1750 1750 1750 1750 1750 1750 1750
				1750 1750 1750 1750 1750 1750 1750 1750 1750 1750 1750 1750 1750 1750 1750 1750 1750 1750
				1750 1750 1750 1750 1750 1750 1750 1750 1750 1750 1750 1750 1750 1750 1750 1750 1750 1750
				1750 1750 1750 1750 1750 1750 1750 1750 1750 1750 1750 1750 1750 1750 1750 1750 1750 1750
				1750 1750 1750 1750 1750 1750 1750 1750 1750 1750 1750 1750 1750 1750 1750 1750 1750 1750
				1750 1750 1750 1750 1750 1750 1750 1750 1750 1750 1750 1750 1750 1750 1750 1750 1750 1750
				1750 1750 1750 1750 1750 1750 1750 1750 1750 1750 1750 1750 1750 1750 1750 1750 1750 1750
				1750 1750 1750 1750 1750 1750 1750 1750 1750 1750 1750 1750 1750 1750 1750 1750 1750 1750
				1750 1750 1750 1750 1750 1750 1750 1750 1750 1750 1750 1750 1750 1750 1750 1750 1750 1750
				1750 1750 1750 1750 1750 1750 1750 1750 1750 1750 1750 1750 1750 1750 1750 1750 1750 1750
				1750 1750 1750 1750 1750 1750 1750 1750 1750 1750 1750 1750 1750 1750 1750 1750 1750 1750
				1750 1750 1750 1750 1750 1750 1750 1750 1750 1750 1750 1750 1750 1750 1750 1750 1750 1750
				1750 1750 1750 1750 1750 1750 1750 1750 1750 1750 1750 1750 1750 1750 1750 1750 1750 1750
				1750 1750 1750 1750 1750 1750 1750 1750 1750 1750 1750 1750 1750 1750 1750 1750 1750 1750
				1750 1750 1750 1750 1750 1750 1750 1750 1750 1750 1750 1750 1750 1750 1750 1750 1750 1750
				1750 1750 1750 1750 1750 1750 1750 1750 1750 1750 1750 1750 1750 1750 1750 1750 1750 1750
				1750 1750 1750 1750 1750 1750 1750 1750 1750 1750 1750 1750 1750 1750 1750 1750 1750 1750
				2000 2000 2000>;

			PS_Config_Lmt_FW_Rawdata_N = <
				  0 650 650 650 650   0   0   0   0   0   0   0   0 650 650 650 650   0
				650 650 650 650 650 650 650 650 650 650 650 650 650 650 650 650 650 650
				650 650 650 650 650 650 650 650 650 650 650 650 650 650 650 650 650 650
				650 650 650 650 650 650 650 650 650 650 650 650 650 650 650 650 650 650
				650 650 650 650 650 650 650 650 650 650 650 650 650 650 650 650 650 650
				650 650 650 650 650 650 650 650 650 650 650 650 650 650 650 650 650 650
				650 650 650 650 650 650 650 650 650 650 650 650 650 650 650 650 650 650
				650 650 650 650 650 650 650 650 650 650 650 650 650 650 650 650 650 650
				650 650 650 650 650 650 650 650 650 650 650 650 650 650 650 650 650 650
				650 650 650 650 650 650 650 650 650 650 650 650 650 650 650 650 650 650
				650 650 650 650 650 650 650 650 650 650 650 650 650 650 650 650 650 650
				650 650 650 650 650 650 650 650 650 650 650 650 650 650 650 650 650 650
				650 650 650 650 650 650 650 650 650 650 650 650 650 650 650 650 650 650
				650 650 650 650 650 650 650 650 650 650 650 650 650 650 650 650 650 650
				650 650 650 650 650 650 650 650 650 650 650 650 650 650 650 650 650 650
				650 650 650 650 650 650 650 650 650 650 650 650 650 650 650 650 650 650
				650 650 650 650 650 650 650 650 650 650 650 650 650 650 650 650 650 650
				650 650 650 650 650 650 650 650 650 650 650 650 650 650 650 650 650 650
				650 650 650 650 650 650 650 650 650 650 650 650 650 650 650 650 650 650
				650 650 650 650 650 650 650 650 650 650 650 650 650 650 650 650 650 650
				650 650 650 650 650 650 650 650 650 650 650 650 650 650 650 650 650 650
				650 650 650 650 650 650 650 650 650 650 650 650 650 650 650 650 650 650
				650 650 650 650 650 650 650 650 650 650 650 650 650 650 650 650 650 650
				650 650 650 650 650 650 650 650 650 650 650 650 650 650 650 650 650 650
				650 650 650 650 650 650 650 650 650 650 650 650 650 650 650 650 650 650
				650 650 650 650 650 650 650 650 650 650 650 650 650 650 650 650 650 650
				650 650 650 650 650 650 650 650 650 650 650 650 650 650 650 650 650 650
				650 650 650 650 650 650 650 650 650 650 650 650 650 650 650 650 650 650
				650 650 650 650 650 650 650 650 650 650 650 650 650 650 650 650 650 650
				650 650 650 650 650 650 650 650 650 650 650 650 650 650 650 650 650 650
				650 650 650 650 650 650 650 650 650 650 650 650 650 650 650 650 650 650
				650 650 650 650 650 650 650 650 650 650 650 650 650 650 650 650 650 650
				650 650 650 650 650 650 650 650 650 650 650 650 650 650 650 650 650 650
				650 650 650 650 650 650 650 650 650 650 650 650 650 650 650 650 650 650
				650 650 650 650 650 650 650 650 650 650 650 650 650 650 650 650 650 650
				650 650 650 650 650 650 650 650 650 650 650 650 650 650 650 650 650 650
				400 400 400>;

			PS_Config_Lmt_FW_CC_P = <
				511 112 111 110 111 511 511 511 511 511 511 511 511 116 114 115 117 511
				121 115 112 111 112 111 111 111 110 111 112 111 112 114 114 114 116 122
				117 112 111 110 110 110 109 109 109 114 114 114 114 115 115 115 117 122
				117 114 112 111 111 111 110 110 110 112 112 112 114 112 114 114 116 120
				117 114 111 111 110 110 110 110 109 114 114 114 114 114 114 115 116 121
				117 114 112 111 111 111 111 110 110 111 111 111 111 111 112 112 114 119
				116 112 110 110 110 110 109 109 107 115 114 115 115 115 115 115 117 121
				117 112 111 111 111 111 111 110 110 112 111 112 112 112 112 114 114 119
				116 112 111 111 111 111 111 110 110 114 112 112 112 112 112 114 115 120
				119 114 112 112 112 112 112 111 111 114 111 112 111 111 112 112 114 117
				116 111 111 111 110 110 111 110 109 116 114 114 114 114 114 114 115 120
				116 111 111 111 110 110 111 110 109 115 112 112 111 111 112 112 112 117
				116 111 111 111 110 111 111 111 109 117 112 112 112 112 112 112 112 117
				117 114 112 112 112 112 112 114 111 116 112 111 111 111 111 111 111 115
				115 111 111 110 110 111 110 112 109 119 114 114 114 112 112 114 114 117
				116 112 111 111 111 111 111 114 110 117 114 112 112 111 112 112 112 116
				116 112 111 111 111 111 111 112 110 119 114 112 112 111 112 112 114 116
				116 112 112 112 111 112 112 112 111 116 111 111 111 110 111 111 111 115
				114 111 110 110 109 110 110 110 109 120 114 114 112 112 112 114 114 117
				115 111 111 111 111 111 111 111 111 119 112 112 112 111 112 112 112 116
				115 112 111 111 111 111 111 111 111 119 112 112 112 111 111 111 112 116
				116 114 114 112 112 112 114 112 111 117 111 111 111 111 111 111 111 115
				114 111 111 111 110 111 111 111 110 120 114 114 114 112 114 114 114 117
				114 111 111 111 110 111 111 111 110 117 111 112 111 111 111 111 111 114
				114 111 111 111 111 111 111 112 110 116 111 111 111 110 111 111 111 114
				116 114 114 114 112 114 114 115 112 115 112 111 111 110 110 110 110 114
				114 111 111 111 111 111 112 114 110 114 115 114 112 112 112 112 112 115
				115 112 112 111 111 114 114 115 111 110 114 111 111 110 111 111 111 114
				115 112 112 112 112 112 114 114 111 110 114 112 111 111 111 111 111 115
				116 114 114 112 112 114 114 115 111 109 111 110 110 109 110 110 110 112
				114 111 111 111 111 111 111 112 110 111 114 114 112 111 111 111 112 115
				116 114 112 112 111 114 114 114 111 110 114 112 111 111 111 111 111 114
				115 114 112 112 112 112 115 115 111 110 114 112 111 111 111 111 111 114
				116 114 114 114 114 114 116 115 112 109 112 112 110 110 110 110 110 112
				114 111 111 111 111 111 115 114 110 110 115 115 112 111 111 111 112 115
				111 110 110 111 110 111 115 114 110 109 114 114 111 110 110 110 109 111
				38 38 38>;

			PS_Config_Lmt_FW_CC_N = <
				0 69 68 67 68 0 0 0 0 0 0 0 0 71 69 70 72 0
				74 70 69 68 69 68 68 68 67 68 69 68 69 69 69 69 71 75
				72 69 68 67 67 67 66 66 66 69 69 69 69 70 70 70 72 75
				72 69 69 68 68 68 67 67 67 69 69 69 69 69 69 69 71 73
				72 69 68 68 67 67 67 67 66 69 69 69 69 69 69 70 71 74
				72 69 69 68 68 68 68 67 67 68 68 68 68 68 69 69 69 72
				71 69 67 67 67 67 66 66 66 70 69 70 70 70 70 70 72 74
				72 69 68 68 68 68 68 67 67 69 68 69 69 69 69 69 69 72
				71 69 68 68 68 68 68 67 67 69 69 69 69 69 69 69 70 73
				72 69 69 69 69 69 69 68 68 69 68 69 68 68 69 69 69 72
				71 68 68 68 67 67 68 67 66 71 69 69 69 69 69 69 70 73
				71 68 68 68 67 67 68 67 66 70 69 69 68 68 69 69 69 72
				71 68 68 68 67 68 68 68 66 72 69 69 69 69 69 69 69 72
				72 69 69 69 69 69 69 69 68 71 69 68 68 68 68 68 68 70
				70 68 68 67 67 68 67 69 66 72 69 69 69 69 69 69 69 72
				71 69 68 68 68 68 68 69 67 72 69 69 69 68 69 69 69 71
				71 69 68 68 68 68 68 69 67 72 69 69 69 68 69 69 69 71
				71 69 69 69 68 69 69 69 68 71 68 68 68 67 68 68 68 70
				69 68 67 67 66 67 67 67 66 73 69 69 69 69 69 69 69 72
				70 68 68 68 68 68 68 68 68 72 69 69 69 68 69 69 69 71
				70 69 68 68 68 68 68 68 68 72 69 69 69 68 68 68 69 71
				71 69 69 69 69 69 69 69 68 72 68 68 68 68 68 68 68 70
				69 68 68 68 67 68 68 68 67 73 69 69 69 69 69 69 69 72
				69 68 68 68 67 68 68 68 67 72 68 69 68 68 68 68 68 69
				69 68 68 68 68 68 68 69 67 71 68 68 68 67 68 68 68 69
				71 69 69 69 69 69 69 70 69 70 69 68 68 67 67 67 67 69
				69 68 68 68 68 68 69 69 67 69 70 69 69 69 69 69 69 70
				70 69 69 68 68 69 69 70 68 67 69 68 68 67 68 68 68 69
				70 69 69 69 69 69 69 69 68 67 69 69 68 68 68 68 68 70
				71 69 69 69 69 69 69 70 68 66 68 67 67 66 67 67 67 69
				69 68 68 68 68 68 68 69 67 68 69 69 69 68 68 68 69 70
				71 69 69 69 68 69 69 69 68 67 69 69 68 68 68 68 68 69
				70 69 69 69 69 69 70 70 68 67 69 69 68 68 68 68 68 69
				71 69 69 69 69 69 71 70 69 66 69 69 67 67 67 67 67 69
				69 68 68 68 68 68 70 69 67 67 70 70 69 68 68 68 69 70
				68 67 67 68 67 68 70 69 67 66 69 69 68 67 67 67 66 68
				9 9 9>;

			PS_Config_Lmt_FW_CC_I_P = <
				25 25 25 25 25 25 25 25 25 25 25 25 25 25 25 25 25 25
				25 25 25 25 25 25 25 25 25 25 25 25 25 25 25 25 25 25
				25 25 25 25 25 25 25 25 25 25 25 25 25 25 25 25 25 25
				25 25 25 25 25 25 25 25 25 25 25 25 25 25 25 25 25 25
				25 25 25 25 25 25 25 25 25 25 25 25 25 25 25 25 25 25
				25 25 25 25 25 25 25 25 25 25 25 25 25 25 25 25 25 25
				25 25 25 25 25 25 25 25 25 25 25 25 25 25 25 25 25 25
				25 25 25 25 25 25 25 25 25 25 25 25 25 25 25 25 25 25
				25 25 25 25 25 25 25 25 25 25 25 25 25 25 25 25 25 25
				25 25 25 25 25 25 25 25 25 25 25 25 25 25 25 25 25 25
				25 25 25 25 25 25 25 25 25 25 25 25 25 25 25 25 25 25
				25 25 25 25 25 25 25 25 25 25 25 25 25 25 25 25 25 25
				25 25 25 25 25 25 25 25 25 25 25 25 25 25 25 25 25 25
				25 25 25 25 25 25 25 25 25 25 25 25 25 25 25 25 25 25
				25 25 25 25 25 25 25 25 25 25 25 25 25 25 25 25 25 25
				25 25 25 25 25 25 25 25 25 25 25 25 25 25 25 25 25 25
				25 25 25 25 25 25 25 25 25 25 25 25 25 25 25 25 25 25
				25 25 25 25 25 25 25 25 25 25 25 25 25 25 25 25 25 25
				25 25 25 25 25 25 25 25 25 25 25 25 25 25 25 25 25 25
				25 25 25 25 25 25 25 25 25 25 25 25 25 25 25 25 25 25
				25 25 25 25 25 25 25 25 25 25 25 25 25 25 25 25 25 25
				25 25 25 25 25 25 25 25 25 25 25 25 25 25 25 25 25 25
				25 25 25 25 25 25 25 25 25 25 25 25 25 25 25 25 25 25
				25 25 25 25 25 25 25 25 25 25 25 25 25 25 25 25 25 25
				25 25 25 25 25 25 25 25 25 25 25 25 25 25 25 25 25 25
				25 25 25 25 25 25 25 25 25 25 25 25 25 25 25 25 25 25
				25 25 25 25 25 25 25 25 25 25 25 25 25 25 25 25 25 25
				25 25 25 25 25 25 25 25 25 25 25 25 25 25 25 25 25 25
				25 25 25 25 25 25 25 25 25 25 25 25 25 25 25 25 25 25
				25 25 25 25 25 25 25 25 25 25 25 25 25 25 25 25 25 25
				25 25 25 25 25 25 25 25 25 25 25 25 25 25 25 25 25 25
				25 25 25 25 25 25 25 25 25 25 25 25 25 25 25 25 25 25
				25 25 25 25 25 25 25 25 25 25 25 25 25 25 25 25 25 25
				25 25 25 25 25 25 25 25 25 25 25 25 25 25 25 25 25 25
				25 25 25 25 25 25 25 25 25 25 25 25 25 25 25 25 25 25
				25 25 25 25 25 25 25 25 25 25 25 25 25 25 25 25 25 25
				25 25 25>;

			PS_Config_Lmt_FW_CC_I_N = <
				0 0 0 0 0 0 0 0 0 0 0 0 0 0 0 0 0 0
				0 0 0 0 0 0 0 0 0 0 0 0 0 0 0 0 0 0
				0 0 0 0 0 0 0 0 0 0 0 0 0 0 0 0 0 0
				0 0 0 0 0 0 0 0 0 0 0 0 0 0 0 0 0 0
				0 0 0 0 0 0 0 0 0 0 0 0 0 0 0 0 0 0
				0 0 0 0 0 0 0 0 0 0 0 0 0 0 0 0 0 0
				0 0 0 0 0 0 0 0 0 0 0 0 0 0 0 0 0 0
				0 0 0 0 0 0 0 0 0 0 0 0 0 0 0 0 0 0
				0 0 0 0 0 0 0 0 0 0 0 0 0 0 0 0 0 0
				0 0 0 0 0 0 0 0 0 0 0 0 0 0 0 0 0 0
				0 0 0 0 0 0 0 0 0 0 0 0 0 0 0 0 0 0
				0 0 0 0 0 0 0 0 0 0 0 0 0 0 0 0 0 0
				0 0 0 0 0 0 0 0 0 0 0 0 0 0 0 0 0 0
				0 0 0 0 0 0 0 0 0 0 0 0 0 0 0 0 0 0
				0 0 0 0 0 0 0 0 0 0 0 0 0 0 0 0 0 0
				0 0 0 0 0 0 0 0 0 0 0 0 0 0 0 0 0 0
				0 0 0 0 0 0 0 0 0 0 0 0 0 0 0 0 0 0
				0 0 0 0 0 0 0 0 0 0 0 0 0 0 0 0 0 0
				0 0 0 0 0 0 0 0 0 0 0 0 0 0 0 0 0 0
				0 0 0 0 0 0 0 0 0 0 0 0 0 0 0 0 0 0
				0 0 0 0 0 0 0 0 0 0 0 0 0 0 0 0 0 0
				0 0 0 0 0 0 0 0 0 0 0 0 0 0 0 0 0 0
				0 0 0 0 0 0 0 0 0 0 0 0 0 0 0 0 0 0
				0 0 0 0 0 0 0 0 0 0 0 0 0 0 0 0 0 0
				0 0 0 0 0 0 0 0 0 0 0 0 0 0 0 0 0 0
				0 0 0 0 0 0 0 0 0 0 0 0 0 0 0 0 0 0
				0 0 0 0 0 0 0 0 0 0 0 0 0 0 0 0 0 0
				0 0 0 0 0 0 0 0 0 0 0 0 0 0 0 0 0 0
				0 0 0 0 0 0 0 0 0 0 0 0 0 0 0 0 0 0
				0 0 0 0 0 0 0 0 0 0 0 0 0 0 0 0 0 0
				0 0 0 0 0 0 0 0 0 0 0 0 0 0 0 0 0 0
				0 0 0 0 0 0 0 0 0 0 0 0 0 0 0 0 0 0
				0 0 0 0 0 0 0 0 0 0 0 0 0 0 0 0 0 0
				0 0 0 0 0 0 0 0 0 0 0 0 0 0 0 0 0 0
				0 0 0 0 0 0 0 0 0 0 0 0 0 0 0 0 0 0
				0 0 0 0 0 0 0 0 0 0 0 0 0 0 0 0 0 0
				0 0 0>;

			PS_Config_Lmt_FW_CC_Q_P = <
				25 25 25 25 25 25 25 25 25 25 25 25 25 25 25 25 25 25
				25 25 25 25 25 25 25 25 25 25 25 25 25 25 25 25 25 25
				25 25 25 25 25 25 25 25 25 25 25 25 25 25 25 25 25 25
				25 25 25 25 25 25 25 25 25 25 25 25 25 25 25 25 25 25
				25 25 25 25 25 25 25 25 25 25 25 25 25 25 25 25 25 25
				25 25 25 25 25 25 25 25 25 25 25 25 25 25 25 25 25 25
				25 25 25 25 25 25 25 25 25 25 25 25 25 25 25 25 25 25
				25 25 25 25 25 25 25 25 25 25 25 25 25 25 25 25 25 25
				25 25 25 25 25 25 25 25 25 25 25 25 25 25 25 25 25 25
				25 25 25 25 25 25 25 25 25 25 25 25 25 25 25 25 25 25
				25 25 25 25 25 25 25 25 25 25 25 25 25 25 25 25 25 25
				25 25 25 25 25 25 25 25 25 25 25 25 25 25 25 25 25 25
				25 25 25 25 25 25 25 25 25 25 25 25 25 25 25 25 25 25
				25 25 25 25 25 25 25 25 25 25 25 25 25 25 25 25 25 25
				25 25 25 25 25 25 25 25 25 25 25 25 25 25 25 25 25 25
				25 25 25 25 25 25 25 25 25 25 25 25 25 25 25 25 25 25
				25 25 25 25 25 25 25 25 25 25 25 25 25 25 25 25 25 25
				25 25 25 25 25 25 25 25 25 25 25 25 25 25 25 25 25 25
				25 25 25 25 25 25 25 25 25 25 25 25 25 25 25 25 25 25
				25 25 25 25 25 25 25 25 25 25 25 25 25 25 25 25 25 25
				25 25 25 25 25 25 25 25 25 25 25 25 25 25 25 25 25 25
				25 25 25 25 25 25 25 25 25 25 25 25 25 25 25 25 25 25
				25 25 25 25 25 25 25 25 25 25 25 25 25 25 25 25 25 25
				25 25 25 25 25 25 25 25 25 25 25 25 25 25 25 25 25 25
				25 25 25 25 25 25 25 25 25 25 25 25 25 25 25 25 25 25
				25 25 25 25 25 25 25 25 25 25 25 25 25 25 25 25 25 25
				25 25 25 25 25 25 25 25 25 25 25 25 25 25 25 25 25 25
				25 25 25 25 25 25 25 25 25 25 25 25 25 25 25 25 25 25
				25 25 25 25 25 25 25 25 25 25 25 25 25 25 25 25 25 25
				25 25 25 25 25 25 25 25 25 25 25 25 25 25 25 25 25 25
				25 25 25 25 25 25 25 25 25 25 25 25 25 25 25 25 25 25
				25 25 25 25 25 25 25 25 25 25 25 25 25 25 25 25 25 25
				25 25 25 25 25 25 25 25 25 25 25 25 25 25 25 25 25 25
				25 25 25 25 25 25 25 25 25 25 25 25 25 25 25 25 25 25
				25 25 25 25 25 25 25 25 25 25 25 25 25 25 25 25 25 25
				25 25 25 25 25 25 25 25 25 25 25 25 25 25 25 25 25 25
				25 25 25>;

			PS_Config_Lmt_FW_CC_Q_N = <
				0 0 0 0 0 0 0 0 0 0 0 0 0 0 0 0 0 0
				0 0 0 0 0 0 0 0 0 0 0 0 0 0 0 0 0 0
				0 0 0 0 0 0 0 0 0 0 0 0 0 0 0 0 0 0
				0 0 0 0 0 0 0 0 0 0 0 0 0 0 0 0 0 0
				0 0 0 0 0 0 0 0 0 0 0 0 0 0 0 0 0 0
				0 0 0 0 0 0 0 0 0 0 0 0 0 0 0 0 0 0
				0 0 0 0 0 0 0 0 0 0 0 0 0 0 0 0 0 0
				0 0 0 0 0 0 0 0 0 0 0 0 0 0 0 0 0 0
				0 0 0 0 0 0 0 0 0 0 0 0 0 0 0 0 0 0
				0 0 0 0 0 0 0 0 0 0 0 0 0 0 0 0 0 0
				0 0 0 0 0 0 0 0 0 0 0 0 0 0 0 0 0 0
				0 0 0 0 0 0 0 0 0 0 0 0 0 0 0 0 0 0
				0 0 0 0 0 0 0 0 0 0 0 0 0 0 0 0 0 0
				0 0 0 0 0 0 0 0 0 0 0 0 0 0 0 0 0 0
				0 0 0 0 0 0 0 0 0 0 0 0 0 0 0 0 0 0
				0 0 0 0 0 0 0 0 0 0 0 0 0 0 0 0 0 0
				0 0 0 0 0 0 0 0 0 0 0 0 0 0 0 0 0 0
				0 0 0 0 0 0 0 0 0 0 0 0 0 0 0 0 0 0
				0 0 0 0 0 0 0 0 0 0 0 0 0 0 0 0 0 0
				0 0 0 0 0 0 0 0 0 0 0 0 0 0 0 0 0 0
				0 0 0 0 0 0 0 0 0 0 0 0 0 0 0 0 0 0
				0 0 0 0 0 0 0 0 0 0 0 0 0 0 0 0 0 0
				0 0 0 0 0 0 0 0 0 0 0 0 0 0 0 0 0 0
				0 0 0 0 0 0 0 0 0 0 0 0 0 0 0 0 0 0
				0 0 0 0 0 0 0 0 0 0 0 0 0 0 0 0 0 0
				0 0 0 0 0 0 0 0 0 0 0 0 0 0 0 0 0 0
				0 0 0 0 0 0 0 0 0 0 0 0 0 0 0 0 0 0
				0 0 0 0 0 0 0 0 0 0 0 0 0 0 0 0 0 0
				0 0 0 0 0 0 0 0 0 0 0 0 0 0 0 0 0 0
				0 0 0 0 0 0 0 0 0 0 0 0 0 0 0 0 0 0
				0 0 0 0 0 0 0 0 0 0 0 0 0 0 0 0 0 0
				0 0 0 0 0 0 0 0 0 0 0 0 0 0 0 0 0 0
				0 0 0 0 0 0 0 0 0 0 0 0 0 0 0 0 0 0
				0 0 0 0 0 0 0 0 0 0 0 0 0 0 0 0 0 0
				0 0 0 0 0 0 0 0 0 0 0 0 0 0 0 0 0 0
				0 0 0 0 0 0 0 0 0 0 0 0 0 0 0 0 0 0
				0 0 0>;

			PS_Config_Lmt_FW_Diff_P = <
				65535 50 50 50 50 65535 65535 65535 65535 65535 65535 65535 65535 50 50 50 50 65535
				50    50 50 50 50 50    50    50    50    50    50    50    50    50 50 50 50 50
				50    50 50 50 50 50    50    50    50    50    50    50    50    50 50 50 50 50
				50    50 50 50 50 50    50    50    50    50    50    50    50    50 50 50 50 50
				50    50 50 50 50 50    50    50    50    50    50    50    50    50 50 50 50 50
				50    50 50 50 50 50    50    50    50    50    50    50    50    50 50 50 50 50
				50    50 50 50 50 50    50    50    50    50    50    50    50    50 50 50 50 50
				50    50 50 50 50 50    50    50    50    50    50    50    50    50 50 50 50 50
				50    50 50 50 50 50    50    50    50    50    50    50    50    50 50 50 50 50
				50    50 50 50 50 50    50    50    50    50    50    50    50    50 50 50 50 50
				50    50 50 50 50 50    50    50    50    50    50    50    50    50 50 50 50 50
				50    50 50 50 50 50    50    50    50    50    50    50    50    50 50 50 50 50
				50    50 50 50 50 50    50    50    50    50    50    50    50    50 50 50 50 50
				50    50 50 50 50 50    50    50    50    50    50    50    50    50 50 50 50 50
				50    50 50 50 50 50    50    50    50    50    50    50    50    50 50 50 50 50
				50    50 50 50 50 50    50    50    50    50    50    50    50    50 50 50 50 50
				50    50 50 50 50 50    50    50    50    50    50    50    50    50 50 50 50 50
				50    50 50 50 50 50    50    50    50    50    50    50    50    50 50 50 50 50
				50    50 50 50 50 50    50    50    50    50    50    50    50    50 50 50 50 50
				50    50 50 50 50 50    50    50    50    50    50    50    50    50 50 50 50 50
				50    50 50 50 50 50    50    50    50    50    50    50    50    50 50 50 50 50
				50    50 50 50 50 50    50    50    50    50    50    50    50    50 50 50 50 50
				50    50 50 50 50 50    50    50    50    50    50    50    50    50 50 50 50 50
				50    50 50 50 50 50    50    50    50    50    50    50    50    50 50 50 50 50
				50    50 50 50 50 50    50    50    50    50    50    50    50    50 50 50 50 50
				50    50 50 50 50 50    50    50    50    50    50    50    50    50 50 50 50 50
				50    50 50 50 50 50    50    50    50    50    50    50    50    50 50 50 50 50
				50    50 50 50 50 50    50    50    50    50    50    50    50    50 50 50 50 50
				50    50 50 50 50 50    50    50    50    50    50    50    50    50 50 50 50 50
				50    50 50 50 50 50    50    50    50    50    50    50    50    50 50 50 50 50
				50    50 50 50 50 50    50    50    50    50    50    50    50    50 50 50 50 50
				50    50 50 50 50 50    50    50    50    50    50    50    50    50 50 50 50 50
				50    50 50 50 50 50    50    50    50    50    50    50    50    50 50 50 50 50
				50    50 50 50 50 50    50    50    50    50    50    50    50    50 50 50 50 50
				50    50 50 50 50 50    50    50    50    50    50    50    50    50 50 50 50 50
				50    50 50 50 50 50    50    50    50    50    50    50    50    50 50 50 50 50
				35 35 35>;

			PS_Config_Lmt_FW_Diff_N = <
				(-65535) (-50) (-50) (-50) (-50) (-65535) (-65535) (-65535) (-65535) (-65535) (-65535) (-65535) (-65535) (-50) (-50) (-50) (-50) (-65535)
				(-50) (-50) (-50) (-50) (-50) (-50) (-50) (-50) (-50) (-50) (-50) (-50) (-50) (-50) (-50) (-50) (-50) (-50)
				(-50) (-50) (-50) (-50) (-50) (-50) (-50) (-50) (-50) (-50) (-50) (-50) (-50) (-50) (-50) (-50) (-50) (-50)
				(-50) (-50) (-50) (-50) (-50) (-50) (-50) (-50) (-50) (-50) (-50) (-50) (-50) (-50) (-50) (-50) (-50) (-50)
				(-50) (-50) (-50) (-50) (-50) (-50) (-50) (-50) (-50) (-50) (-50) (-50) (-50) (-50) (-50) (-50) (-50) (-50)
				(-50) (-50) (-50) (-50) (-50) (-50) (-50) (-50) (-50) (-50) (-50) (-50) (-50) (-50) (-50) (-50) (-50) (-50)
				(-50) (-50) (-50) (-50) (-50) (-50) (-50) (-50) (-50) (-50) (-50) (-50) (-50) (-50) (-50) (-50) (-50) (-50)
				(-50) (-50) (-50) (-50) (-50) (-50) (-50) (-50) (-50) (-50) (-50) (-50) (-50) (-50) (-50) (-50) (-50) (-50)
				(-50) (-50) (-50) (-50) (-50) (-50) (-50) (-50) (-50) (-50) (-50) (-50) (-50) (-50) (-50) (-50) (-50) (-50)
				(-50) (-50) (-50) (-50) (-50) (-50) (-50) (-50) (-50) (-50) (-50) (-50) (-50) (-50) (-50) (-50) (-50) (-50)
				(-50) (-50) (-50) (-50) (-50) (-50) (-50) (-50) (-50) (-50) (-50) (-50) (-50) (-50) (-50) (-50) (-50) (-50)
				(-50) (-50) (-50) (-50) (-50) (-50) (-50) (-50) (-50) (-50) (-50) (-50) (-50) (-50) (-50) (-50) (-50) (-50)
				(-50) (-50) (-50) (-50) (-50) (-50) (-50) (-50) (-50) (-50) (-50) (-50) (-50) (-50) (-50) (-50) (-50) (-50)
				(-50) (-50) (-50) (-50) (-50) (-50) (-50) (-50) (-50) (-50) (-50) (-50) (-50) (-50) (-50) (-50) (-50) (-50)
				(-50) (-50) (-50) (-50) (-50) (-50) (-50) (-50) (-50) (-50) (-50) (-50) (-50) (-50) (-50) (-50) (-50) (-50)
				(-50) (-50) (-50) (-50) (-50) (-50) (-50) (-50) (-50) (-50) (-50) (-50) (-50) (-50) (-50) (-50) (-50) (-50)
				(-50) (-50) (-50) (-50) (-50) (-50) (-50) (-50) (-50) (-50) (-50) (-50) (-50) (-50) (-50) (-50) (-50) (-50)
				(-50) (-50) (-50) (-50) (-50) (-50) (-50) (-50) (-50) (-50) (-50) (-50) (-50) (-50) (-50) (-50) (-50) (-50)
				(-50) (-50) (-50) (-50) (-50) (-50) (-50) (-50) (-50) (-50) (-50) (-50) (-50) (-50) (-50) (-50) (-50) (-50)
				(-50) (-50) (-50) (-50) (-50) (-50) (-50) (-50) (-50) (-50) (-50) (-50) (-50) (-50) (-50) (-50) (-50) (-50)
				(-50) (-50) (-50) (-50) (-50) (-50) (-50) (-50) (-50) (-50) (-50) (-50) (-50) (-50) (-50) (-50) (-50) (-50)
				(-50) (-50) (-50) (-50) (-50) (-50) (-50) (-50) (-50) (-50) (-50) (-50) (-50) (-50) (-50) (-50) (-50) (-50)
				(-50) (-50) (-50) (-50) (-50) (-50) (-50) (-50) (-50) (-50) (-50) (-50) (-50) (-50) (-50) (-50) (-50) (-50)
				(-50) (-50) (-50) (-50) (-50) (-50) (-50) (-50) (-50) (-50) (-50) (-50) (-50) (-50) (-50) (-50) (-50) (-50)
				(-50) (-50) (-50) (-50) (-50) (-50) (-50) (-50) (-50) (-50) (-50) (-50) (-50) (-50) (-50) (-50) (-50) (-50)
				(-50) (-50) (-50) (-50) (-50) (-50) (-50) (-50) (-50) (-50) (-50) (-50) (-50) (-50) (-50) (-50) (-50) (-50)
				(-50) (-50) (-50) (-50) (-50) (-50) (-50) (-50) (-50) (-50) (-50) (-50) (-50) (-50) (-50) (-50) (-50) (-50)
				(-50) (-50) (-50) (-50) (-50) (-50) (-50) (-50) (-50) (-50) (-50) (-50) (-50) (-50) (-50) (-50) (-50) (-50)
				(-50) (-50) (-50) (-50) (-50) (-50) (-50) (-50) (-50) (-50) (-50) (-50) (-50) (-50) (-50) (-50) (-50) (-50)
				(-50) (-50) (-50) (-50) (-50) (-50) (-50) (-50) (-50) (-50) (-50) (-50) (-50) (-50) (-50) (-50) (-50) (-50)
				(-50) (-50) (-50) (-50) (-50) (-50) (-50) (-50) (-50) (-50) (-50) (-50) (-50) (-50) (-50) (-50) (-50) (-50)
				(-50) (-50) (-50) (-50) (-50) (-50) (-50) (-50) (-50) (-50) (-50) (-50) (-50) (-50) (-50) (-50) (-50) (-50)
				(-50) (-50) (-50) (-50) (-50) (-50) (-50) (-50) (-50) (-50) (-50) (-50) (-50) (-50) (-50) (-50) (-50) (-50)
				(-50) (-50) (-50) (-50) (-50) (-50) (-50) (-50) (-50) (-50) (-50) (-50) (-50) (-50) (-50) (-50) (-50) (-50)
				(-50) (-50) (-50) (-50) (-50) (-50) (-50) (-50) (-50) (-50) (-50) (-50) (-50) (-50) (-50) (-50) (-50) (-50)
				(-50) (-50) (-50) (-50) (-50) (-50) (-50) (-50) (-50) (-50) (-50) (-50) (-50) (-50) (-50) (-50) (-50) (-50)
				(-35) (-35) (-35)>;
			PS_Config_Diff_Test_Frame = <50>;
		};
	};

};
